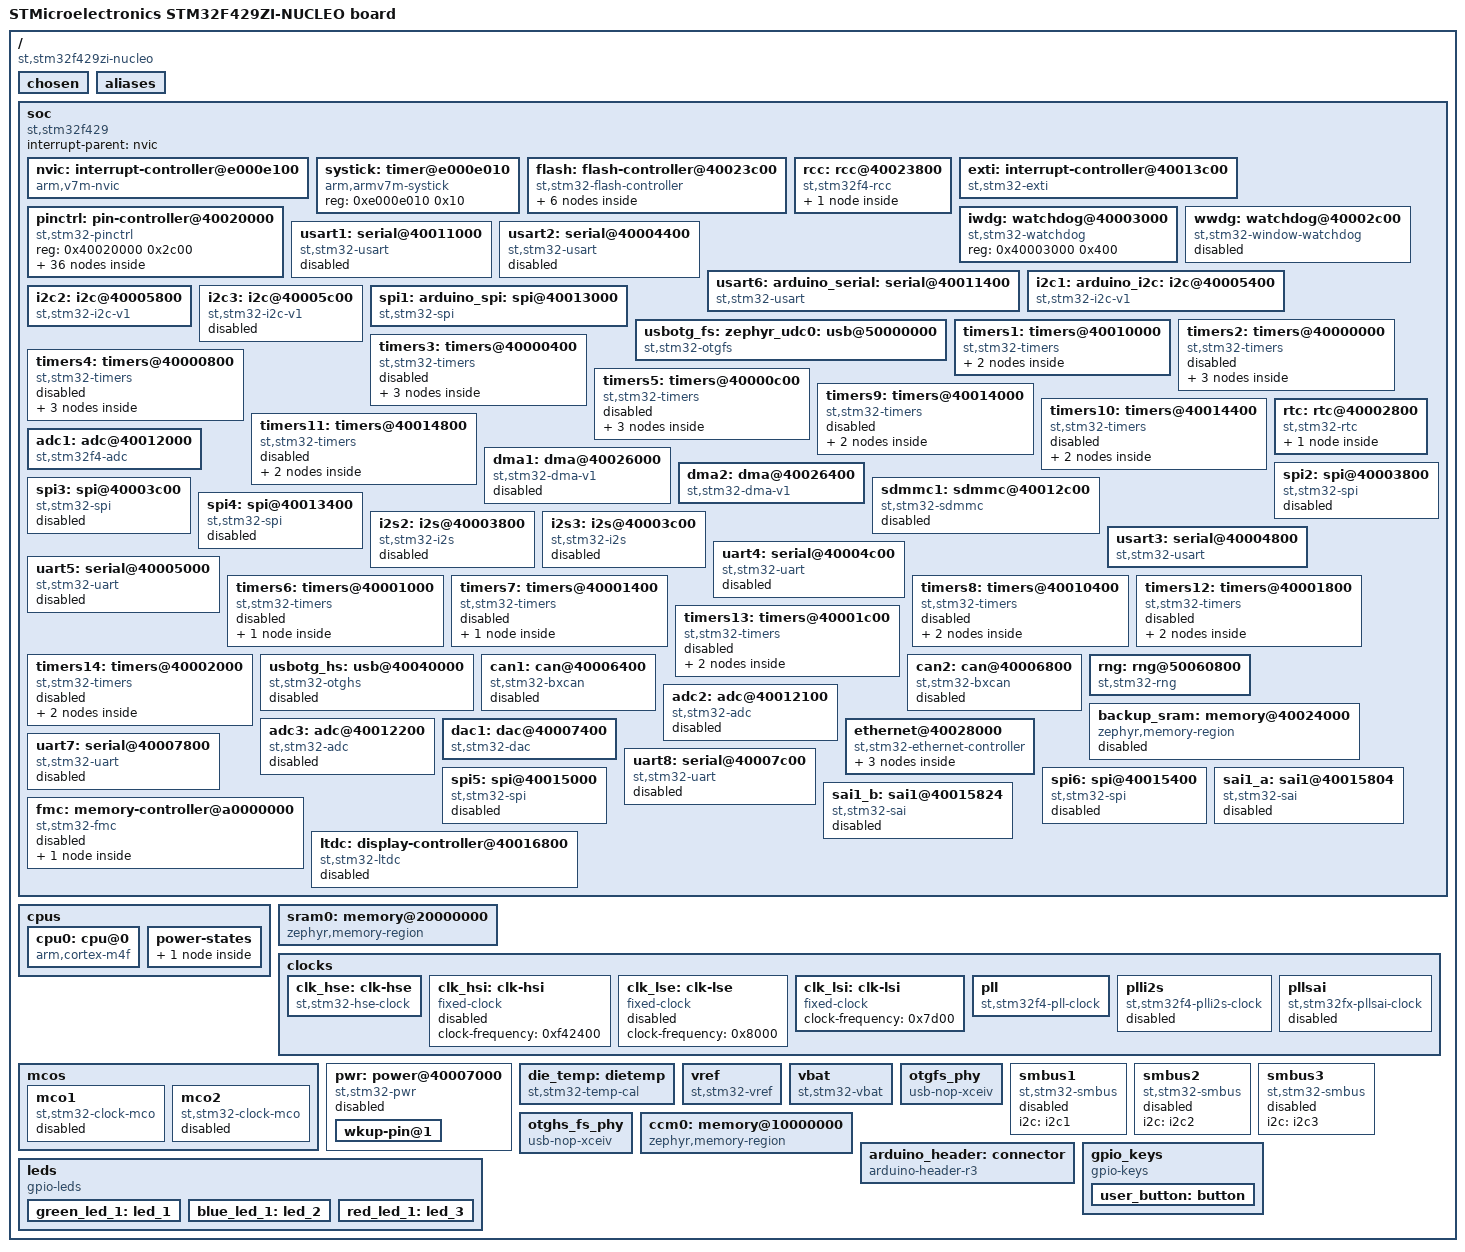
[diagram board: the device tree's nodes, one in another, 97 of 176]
/dts-v1/;

/* node '/' defined in zephyr/dts/common/skeleton.dtsi:9 */
/ {
	#address-cells = < 0x1 >;                              /* in zephyr/dts/common/skeleton.dtsi:10 */
	#size-cells = < 0x1 >;                                 /* in zephyr/dts/common/skeleton.dtsi:11 */
	model = "STMicroelectronics STM32F429ZI-NUCLEO board"; /* in zephyr/boards/st/nucleo_f429zi/nucleo_f429zi.dts:14 */
	compatible = "st,stm32f429zi-nucleo";                  /* in zephyr/boards/st/nucleo_f429zi/nucleo_f429zi.dts:15 */

	/* node '/chosen' defined in zephyr/dts/common/skeleton.dtsi:13 */
	chosen {
		zephyr,flash-controller = &flash;         /* in zephyr/dts/arm/st/f4/stm32f4.dtsi:27 */
		zephyr,cortex-m-idle-timer = &rtc;        /* in zephyr/dts/arm/st/f4/stm32f4.dtsi:28 */
		zephyr,entropy = &rng;                    /* in zephyr/dts/arm/st/f4/stm32f405.dtsi:13 */
		zephyr,console = &usart3;                 /* in zephyr/boards/st/nucleo_f429zi/nucleo_f429zi.dts:18 */
		zephyr,shell-uart = &usart3;              /* in zephyr/boards/st/nucleo_f429zi/nucleo_f429zi.dts:19 */
		zephyr,sram = &sram0;                     /* in zephyr/boards/st/nucleo_f429zi/nucleo_f429zi.dts:20 */
		zephyr,flash = &flash0;                   /* in zephyr/boards/st/nucleo_f429zi/nucleo_f429zi.dts:21 */
		zephyr,ccm = &ccm0;                       /* in zephyr/boards/st/nucleo_f429zi/nucleo_f429zi.dts:22 */
		zephyr,code-partition = &slot0_partition; /* in zephyr/boards/st/nucleo_f429zi/nucleo_f429zi.dts:23 */
	};

	/* node '/aliases' defined in zephyr/dts/common/skeleton.dtsi:15 */
	aliases {
		led0 = &green_led_1;   /* in zephyr/boards/st/nucleo_f429zi/nucleo_f429zi.dts:56 */
		led1 = &blue_led_1;    /* in zephyr/boards/st/nucleo_f429zi/nucleo_f429zi.dts:57 */
		led2 = &red_led_1;     /* in zephyr/boards/st/nucleo_f429zi/nucleo_f429zi.dts:58 */
		sw0 = &user_button;    /* in zephyr/boards/st/nucleo_f429zi/nucleo_f429zi.dts:59 */
		watchdog0 = &iwdg;     /* in zephyr/boards/st/nucleo_f429zi/nucleo_f429zi.dts:60 */
		die-temp0 = &die_temp; /* in zephyr/boards/st/nucleo_f429zi/nucleo_f429zi.dts:61 */
		volt-sensor0 = &vref;  /* in zephyr/boards/st/nucleo_f429zi/nucleo_f429zi.dts:62 */
		volt-sensor1 = &vbat;  /* in zephyr/boards/st/nucleo_f429zi/nucleo_f429zi.dts:63 */
	};

	/* node '/soc' defined in zephyr/dts/arm/armv7-m.dtsi:6 */
	soc {
		#address-cells = < 0x1 >;     /* in zephyr/dts/arm/armv7-m.dtsi:7 */
		#size-cells = < 0x1 >;        /* in zephyr/dts/arm/armv7-m.dtsi:8 */
		interrupt-parent = < &nvic >; /* in zephyr/dts/arm/armv7-m.dtsi:10 */
		ranges;                       /* in zephyr/dts/arm/armv7-m.dtsi:11 */
		compatible = "st,stm32f429",
		             "st,stm32f4",
		             "simple-bus";    /* in zephyr/dts/arm/st/f4/stm32f429.dtsi:12 */

		/* node '/soc/interrupt-controller@e000e100' defined in zephyr/dts/arm/armv7-m.dtsi:13 */
		nvic: interrupt-controller@e000e100 {
			#address-cells = < 0x1 >;            /* in zephyr/dts/arm/armv7-m.dtsi:14 */
			compatible = "arm,v7m-nvic";         /* in zephyr/dts/arm/armv7-m.dtsi:15 */
			reg = < 0xe000e100 0xc00 >;          /* in zephyr/dts/arm/armv7-m.dtsi:16 */
			interrupt-controller;                /* in zephyr/dts/arm/armv7-m.dtsi:17 */
			#interrupt-cells = < 0x2 >;          /* in zephyr/dts/arm/armv7-m.dtsi:18 */
			arm,num-irq-priority-bits = < 0x4 >; /* in zephyr/dts/arm/st/f4/stm32f4.dtsi:676 */
			phandle = < 0x1 >;                   /* in zephyr/dts/arm/armv7-m.dtsi:10 */
		};

		/* node '/soc/timer@e000e010' defined in zephyr/dts/arm/armv7-m.dtsi:21 */
		systick: timer@e000e010 {
			compatible = "arm,armv7m-systick"; /* in zephyr/dts/arm/armv7-m.dtsi:22 */
			reg = < 0xe000e010 0x10 >;         /* in zephyr/dts/arm/armv7-m.dtsi:23 */
		};

		/* node '/soc/flash-controller@40023c00' defined in zephyr/dts/arm/st/f4/stm32f4.dtsi:111 */
		flash: flash-controller@40023c00 {
			compatible = "st,stm32-flash-controller",
			             "st,stm32f4-flash-controller"; /* in zephyr/dts/arm/st/f4/stm32f4.dtsi:112 */
			reg = < 0x40023c00 0x400 >;                 /* in zephyr/dts/arm/st/f4/stm32f4.dtsi:113 */
			interrupts = < 0x4 0x0 >;                   /* in zephyr/dts/arm/st/f4/stm32f4.dtsi:114 */
			#address-cells = < 0x1 >;                   /* in zephyr/dts/arm/st/f4/stm32f4.dtsi:116 */
			#size-cells = < 0x1 >;                      /* in zephyr/dts/arm/st/f4/stm32f4.dtsi:117 */

			/* node '/soc/flash-controller@40023c00/flash@8000000' defined in zephyr/dts/arm/st/f4/stm32f4.dtsi:119 */
			flash0: flash@8000000 {
				compatible = "st,stm32f4-nv-flash",
				             "st,stm32-nv-flash",
				             "soc-nv-flash";        /* in zephyr/dts/arm/st/f4/stm32f4.dtsi:120 */
				write-block-size = < 0x1 >;         /* in zephyr/dts/arm/st/f4/stm32f4.dtsi:123 */
				max-erase-time = < 0xfa0 >;         /* in zephyr/dts/arm/st/f4/stm32f4.dtsi:125 */
				reg = < 0x8000000 0x200000 >;       /* in zephyr/dts/arm/st/f4/stm32f429Xi.dtsi:23 */

				/* node '/soc/flash-controller@40023c00/flash@8000000/partitions' defined in zephyr/boards/st/nucleo_f429zi/nucleo_f429zi.dts:208 */
				partitions {
					compatible = "fixed-partitions"; /* in zephyr/boards/st/nucleo_f429zi/nucleo_f429zi.dts:209 */
					#address-cells = < 0x1 >;        /* in zephyr/boards/st/nucleo_f429zi/nucleo_f429zi.dts:210 */
					#size-cells = < 0x1 >;           /* in zephyr/boards/st/nucleo_f429zi/nucleo_f429zi.dts:211 */

					/* node '/soc/flash-controller@40023c00/flash@8000000/partitions/partition@0' defined in zephyr/boards/st/nucleo_f429zi/nucleo_f429zi.dts:214 */
					boot_partition: partition@0 {
						label = "mcuboot";    /* in zephyr/boards/st/nucleo_f429zi/nucleo_f429zi.dts:215 */
						reg = < 0x0 0x8000 >; /* in zephyr/boards/st/nucleo_f429zi/nucleo_f429zi.dts:216 */
						read-only;            /* in zephyr/boards/st/nucleo_f429zi/nucleo_f429zi.dts:217 */
					};

					/* node '/soc/flash-controller@40023c00/flash@8000000/partitions/partition@20000' defined in zephyr/boards/st/nucleo_f429zi/nucleo_f429zi.dts:233 */
					slot0_partition: partition@20000 {
						label = "image-0";         /* in zephyr/boards/st/nucleo_f429zi/nucleo_f429zi.dts:234 */
						reg = < 0x20000 0x40000 >; /* in zephyr/boards/st/nucleo_f429zi/nucleo_f429zi.dts:235 */
					};

					/* node '/soc/flash-controller@40023c00/flash@8000000/partitions/partition@60000' defined in zephyr/boards/st/nucleo_f429zi/nucleo_f429zi.dts:239 */
					slot1_partition: partition@60000 {
						label = "image-1";         /* in zephyr/boards/st/nucleo_f429zi/nucleo_f429zi.dts:240 */
						reg = < 0x60000 0x40000 >; /* in zephyr/boards/st/nucleo_f429zi/nucleo_f429zi.dts:241 */
					};

					/* node '/soc/flash-controller@40023c00/flash@8000000/partitions/partition@a0000' defined in zephyr/boards/st/nucleo_f429zi/nucleo_f429zi.dts:245 */
					scratch_partition: partition@a0000 {
						label = "image-scratch";   /* in zephyr/boards/st/nucleo_f429zi/nucleo_f429zi.dts:246 */
						reg = < 0xa0000 0x20000 >; /* in zephyr/boards/st/nucleo_f429zi/nucleo_f429zi.dts:247 */
					};
				};
			};
		};

		/* node '/soc/rcc@40023800' defined in zephyr/dts/arm/st/f4/stm32f4.dtsi:129 */
		rcc: rcc@40023800 {
			#clock-cells = < 0x2 >;          /* in zephyr/dts/arm/st/f4/stm32f4.dtsi:131 */
			reg = < 0x40023800 0x400 >;      /* in zephyr/dts/arm/st/f4/stm32f4.dtsi:132 */
			compatible = "st,stm32f4-rcc";   /* in zephyr/dts/arm/st/f4/stm32f427.dtsi:25 */
			clocks = < &pll >;               /* in zephyr/boards/st/nucleo_f429zi/nucleo_f429zi.dts:87 */
			clock-frequency = < 0xa037a00 >; /* in zephyr/boards/st/nucleo_f429zi/nucleo_f429zi.dts:88 */
			ahb-prescaler = < 0x1 >;         /* in zephyr/boards/st/nucleo_f429zi/nucleo_f429zi.dts:89 */
			apb1-prescaler = < 0x4 >;        /* in zephyr/boards/st/nucleo_f429zi/nucleo_f429zi.dts:90 */
			apb2-prescaler = < 0x2 >;        /* in zephyr/boards/st/nucleo_f429zi/nucleo_f429zi.dts:91 */
			phandle = < 0x3 >;               /* in zephyr/dts/arm/st/f4/stm32f4.dtsi:146 */

			/* node '/soc/rcc@40023800/reset-controller' defined in zephyr/dts/arm/st/f4/stm32f4.dtsi:134 */
			rctl: reset-controller {
				compatible = "st,stm32-rcc-rctl"; /* in zephyr/dts/arm/st/f4/stm32f4.dtsi:135 */
				#reset-cells = < 0x1 >;           /* in zephyr/dts/arm/st/f4/stm32f4.dtsi:136 */
				phandle = < 0x4 >;                /* in zephyr/dts/arm/st/f4/stm32f4.dtsi:245 */
			};
		};

		/* node '/soc/interrupt-controller@40013c00' defined in zephyr/dts/arm/st/f4/stm32f4.dtsi:140 */
		exti: interrupt-controller@40013c00 {
			compatible = "st,stm32-exti";  /* in zephyr/dts/arm/st/f4/stm32f4.dtsi:141 */
			interrupt-controller;          /* in zephyr/dts/arm/st/f4/stm32f4.dtsi:142 */
			#interrupt-cells = < 0x1 >;    /* in zephyr/dts/arm/st/f4/stm32f4.dtsi:143 */
			#address-cells = < 0x0 >;      /* in zephyr/dts/arm/st/f4/stm32f4.dtsi:144 */
			reg = < 0x40013c00 0x400 >;    /* in zephyr/dts/arm/st/f4/stm32f4.dtsi:145 */
			clocks = < &rcc 0x44 0x4000 >; /* in zephyr/dts/arm/st/f4/stm32f4.dtsi:146 */
			num-lines = < 0x20 >;          /* in zephyr/dts/arm/st/f4/stm32f4.dtsi:147 */
			interrupts = < 0x6 0x0 >,
			             < 0x7 0x0 >,
			             < 0x8 0x0 >,
			             < 0x9 0x0 >,
			             < 0xa 0x0 >,
			             < 0x17 0x0 >,
			             < 0x28 0x0 >;     /* in zephyr/dts/arm/st/f4/stm32f4.dtsi:148 */
			interrupt-names = "line0",
			                  "line1",
			                  "line2",
			                  "line3",
			                  "line4",
			                  "line5-9",
			                  "line10-15"; /* in zephyr/dts/arm/st/f4/stm32f4.dtsi:150 */
			line-ranges = < 0x0 0x1 >,
			              < 0x1 0x1 >,
			              < 0x2 0x1 >,
			              < 0x3 0x1 >,
			              < 0x4 0x1 >,
			              < 0x5 0x5 >,
			              < 0xa 0x6 >;     /* in zephyr/dts/arm/st/f4/stm32f4.dtsi:152 */
		};

		/* node '/soc/pin-controller@40020000' defined in zephyr/dts/arm/st/f4/stm32f4.dtsi:156 */
		pinctrl: pin-controller@40020000 {
			compatible = "st,stm32-pinctrl"; /* in zephyr/dts/arm/st/f4/stm32f4.dtsi:157 */
			#address-cells = < 0x1 >;        /* in zephyr/dts/arm/st/f4/stm32f4.dtsi:158 */
			#size-cells = < 0x1 >;           /* in zephyr/dts/arm/st/f4/stm32f4.dtsi:159 */
			reg = < 0x40020000 0x2c00 >;     /* in zephyr/dts/arm/st/f4/stm32f427.dtsi:29 */

			/* node '/soc/pin-controller@40020000/gpio@40020000' defined in zephyr/dts/arm/st/f4/stm32f4.dtsi:162 */
			gpioa: gpio@40020000 {
				compatible = "st,stm32-gpio"; /* in zephyr/dts/arm/st/f4/stm32f4.dtsi:163 */
				gpio-controller;              /* in zephyr/dts/arm/st/f4/stm32f4.dtsi:164 */
				#gpio-cells = < 0x2 >;        /* in zephyr/dts/arm/st/f4/stm32f4.dtsi:165 */
				reg = < 0x40020000 0x400 >;   /* in zephyr/dts/arm/st/f4/stm32f4.dtsi:166 */
				clocks = < &rcc 0x30 0x1 >;   /* in zephyr/dts/arm/st/f4/stm32f4.dtsi:167 */
				phandle = < 0x26 >;           /* in zephyr/dts/arm/st/f4/stm32f4.dtsi:615 */
			};

			/* node '/soc/pin-controller@40020000/gpio@40020400' defined in zephyr/dts/arm/st/f4/stm32f4.dtsi:170 */
			gpiob: gpio@40020400 {
				compatible = "st,stm32-gpio"; /* in zephyr/dts/arm/st/f4/stm32f4.dtsi:171 */
				gpio-controller;              /* in zephyr/dts/arm/st/f4/stm32f4.dtsi:172 */
				#gpio-cells = < 0x2 >;        /* in zephyr/dts/arm/st/f4/stm32f4.dtsi:173 */
				reg = < 0x40020400 0x400 >;   /* in zephyr/dts/arm/st/f4/stm32f4.dtsi:174 */
				clocks = < &rcc 0x30 0x2 >;   /* in zephyr/dts/arm/st/f4/stm32f4.dtsi:175 */
				phandle = < 0x2f >;           /* in zephyr/boards/st/nucleo_f429zi/arduino_r3_connector.dtsi:15 */
			};

			/* node '/soc/pin-controller@40020000/gpio@40020800' defined in zephyr/dts/arm/st/f4/stm32f4.dtsi:178 */
			gpioc: gpio@40020800 {
				compatible = "st,stm32-gpio"; /* in zephyr/dts/arm/st/f4/stm32f4.dtsi:179 */
				gpio-controller;              /* in zephyr/dts/arm/st/f4/stm32f4.dtsi:180 */
				#gpio-cells = < 0x2 >;        /* in zephyr/dts/arm/st/f4/stm32f4.dtsi:181 */
				reg = < 0x40020800 0x400 >;   /* in zephyr/dts/arm/st/f4/stm32f4.dtsi:182 */
				clocks = < &rcc 0x30 0x4 >;   /* in zephyr/dts/arm/st/f4/stm32f4.dtsi:183 */
				phandle = < 0x2b >;           /* in zephyr/boards/st/nucleo_f429zi/arduino_r3_connector.dtsi:15 */
			};

			/* node '/soc/pin-controller@40020000/gpio@40020c00' defined in zephyr/dts/arm/st/f4/stm32f4.dtsi:186 */
			gpiod: gpio@40020c00 {
				compatible = "st,stm32-gpio"; /* in zephyr/dts/arm/st/f4/stm32f4.dtsi:187 */
				gpio-controller;              /* in zephyr/dts/arm/st/f4/stm32f4.dtsi:188 */
				#gpio-cells = < 0x2 >;        /* in zephyr/dts/arm/st/f4/stm32f4.dtsi:189 */
				reg = < 0x40020c00 0x400 >;   /* in zephyr/dts/arm/st/f4/stm32f4.dtsi:190 */
				clocks = < &rcc 0x30 0x8 >;   /* in zephyr/dts/arm/st/f4/stm32f4.dtsi:191 */
				phandle = < 0xe >;            /* in zephyr/boards/st/nucleo_f429zi/nucleo_f429zi.dts:129 */
			};

			/* node '/soc/pin-controller@40020000/gpio@40021000' defined in zephyr/dts/arm/st/f4/stm32f4.dtsi:194 */
			gpioe: gpio@40021000 {
				compatible = "st,stm32-gpio"; /* in zephyr/dts/arm/st/f4/stm32f4.dtsi:195 */
				gpio-controller;              /* in zephyr/dts/arm/st/f4/stm32f4.dtsi:196 */
				#gpio-cells = < 0x2 >;        /* in zephyr/dts/arm/st/f4/stm32f4.dtsi:197 */
				reg = < 0x40021000 0x400 >;   /* in zephyr/dts/arm/st/f4/stm32f4.dtsi:198 */
				clocks = < &rcc 0x30 0x10 >;  /* in zephyr/dts/arm/st/f4/stm32f4.dtsi:199 */
				phandle = < 0x2e >;           /* in zephyr/boards/st/nucleo_f429zi/arduino_r3_connector.dtsi:15 */
			};

			/* node '/soc/pin-controller@40020000/gpio@40021400' defined in zephyr/dts/arm/st/f4/stm32f4.dtsi:202 */
			gpiof: gpio@40021400 {
				compatible = "st,stm32-gpio"; /* in zephyr/dts/arm/st/f4/stm32f405.dtsi:27 */
				gpio-controller;              /* in zephyr/dts/arm/st/f4/stm32f405.dtsi:28 */
				#gpio-cells = < 0x2 >;        /* in zephyr/dts/arm/st/f4/stm32f405.dtsi:29 */
				reg = < 0x40021400 0x400 >;   /* in zephyr/dts/arm/st/f4/stm32f405.dtsi:30 */
				clocks = < &rcc 0x30 0x20 >;  /* in zephyr/dts/arm/st/f4/stm32f405.dtsi:31 */
				phandle = < 0x2c >;           /* in zephyr/boards/st/nucleo_f429zi/arduino_r3_connector.dtsi:15 */
			};

			/* node '/soc/pin-controller@40020000/gpio@40021800' defined in zephyr/dts/arm/st/f4/stm32f4.dtsi:210 */
			gpiog: gpio@40021800 {
				compatible = "st,stm32-gpio"; /* in zephyr/dts/arm/st/f4/stm32f405.dtsi:35 */
				gpio-controller;              /* in zephyr/dts/arm/st/f4/stm32f405.dtsi:36 */
				#gpio-cells = < 0x2 >;        /* in zephyr/dts/arm/st/f4/stm32f405.dtsi:37 */
				reg = < 0x40021800 0x400 >;   /* in zephyr/dts/arm/st/f4/stm32f405.dtsi:38 */
				clocks = < &rcc 0x30 0x40 >;  /* in zephyr/dts/arm/st/f4/stm32f405.dtsi:39 */
				phandle = < 0x2d >;           /* in zephyr/boards/st/nucleo_f429zi/arduino_r3_connector.dtsi:15 */
			};

			/* node '/soc/pin-controller@40020000/gpio@40021c00' defined in zephyr/dts/arm/st/f4/stm32f4.dtsi:218 */
			gpioh: gpio@40021c00 {
				compatible = "st,stm32-gpio"; /* in zephyr/dts/arm/st/f4/stm32f4.dtsi:219 */
				gpio-controller;              /* in zephyr/dts/arm/st/f4/stm32f4.dtsi:220 */
				#gpio-cells = < 0x2 >;        /* in zephyr/dts/arm/st/f4/stm32f4.dtsi:221 */
				reg = < 0x40021c00 0x400 >;   /* in zephyr/dts/arm/st/f4/stm32f4.dtsi:222 */
				clocks = < &rcc 0x30 0x80 >;  /* in zephyr/dts/arm/st/f4/stm32f4.dtsi:223 */
			};

			/* node '/soc/pin-controller@40020000/gpio@40022000' defined in zephyr/dts/arm/st/f4/stm32f405.dtsi:42 */
			gpioi: gpio@40022000 {
				compatible = "st,stm32-gpio"; /* in zephyr/dts/arm/st/f4/stm32f405.dtsi:43 */
				gpio-controller;              /* in zephyr/dts/arm/st/f4/stm32f405.dtsi:44 */
				#gpio-cells = < 0x2 >;        /* in zephyr/dts/arm/st/f4/stm32f405.dtsi:45 */
				reg = < 0x40022000 0x400 >;   /* in zephyr/dts/arm/st/f4/stm32f405.dtsi:46 */
				clocks = < &rcc 0x30 0x100 >; /* in zephyr/dts/arm/st/f4/stm32f405.dtsi:47 */
			};

			/* node '/soc/pin-controller@40020000/gpio@40022400' defined in zephyr/dts/arm/st/f4/stm32f427.dtsi:31 */
			gpioj: gpio@40022400 {
				compatible = "st,stm32-gpio"; /* in zephyr/dts/arm/st/f4/stm32f427.dtsi:32 */
				gpio-controller;              /* in zephyr/dts/arm/st/f4/stm32f427.dtsi:33 */
				#gpio-cells = < 0x2 >;        /* in zephyr/dts/arm/st/f4/stm32f427.dtsi:34 */
				reg = < 0x40022400 0x400 >;   /* in zephyr/dts/arm/st/f4/stm32f427.dtsi:35 */
				clocks = < &rcc 0x30 0x200 >; /* in zephyr/dts/arm/st/f4/stm32f427.dtsi:36 */
			};

			/* node '/soc/pin-controller@40020000/gpio@40022800' defined in zephyr/dts/arm/st/f4/stm32f427.dtsi:39 */
			gpiok: gpio@40022800 {
				compatible = "st,stm32-gpio"; /* in zephyr/dts/arm/st/f4/stm32f427.dtsi:40 */
				gpio-controller;              /* in zephyr/dts/arm/st/f4/stm32f427.dtsi:41 */
				#gpio-cells = < 0x2 >;        /* in zephyr/dts/arm/st/f4/stm32f427.dtsi:42 */
				reg = < 0x40022800 0x400 >;   /* in zephyr/dts/arm/st/f4/stm32f427.dtsi:43 */
				clocks = < &rcc 0x30 0x400 >; /* in zephyr/dts/arm/st/f4/stm32f427.dtsi:44 */
			};

			/* node '/soc/pin-controller@40020000/adc1_in0_pa0' defined in modules/hal/stm32/dts/st/f4/stm32f429zitx-pinctrl.dtsi:15 */
			adc1_in0_pa0: adc1_in0_pa0 {
				pinmux = < 0x10 >;  /* in modules/hal/stm32/dts/st/f4/stm32f429zitx-pinctrl.dtsi:16 */
				phandle = < 0x13 >; /* in zephyr/boards/st/nucleo_f429zi/nucleo_f429zi.dts:95 */
			};

			/* node '/soc/pin-controller@40020000/dac_out1_pa4' defined in modules/hal/stm32/dts/st/f4/stm32f429zitx-pinctrl.dtsi:716 */
			dac_out1_pa4: dac_out1_pa4 {
				pinmux = < 0x90 >;  /* in modules/hal/stm32/dts/st/f4/stm32f429zitx-pinctrl.dtsi:717 */
				phandle = < 0x18 >; /* in zephyr/boards/st/nucleo_f429zi/nucleo_f429zi.dts:108 */
			};

			/* node '/soc/pin-controller@40020000/eth_ref_clk_pa1' defined in modules/hal/stm32/dts/st/f4/stm32f429zitx-pinctrl.dtsi:893 */
			eth_ref_clk_pa1: eth_ref_clk_pa1 {
				pinmux = < 0x2b >;             /* in modules/hal/stm32/dts/st/f4/stm32f429zitx-pinctrl.dtsi:894 */
				slew-rate = "very-high-speed"; /* in modules/hal/stm32/dts/st/f4/stm32f429zitx-pinctrl.dtsi:895 */
				phandle = < 0x1b >;            /* in zephyr/boards/st/nucleo_f429zi/nucleo_f429zi.dts:184 */
			};

			/* node '/soc/pin-controller@40020000/eth_mdio_pa2' defined in modules/hal/stm32/dts/st/f4/stm32f429zitx-pinctrl.dtsi:903 */
			eth_mdio_pa2: eth_mdio_pa2 {
				pinmux = < 0x4b >;             /* in modules/hal/stm32/dts/st/f4/stm32f429zitx-pinctrl.dtsi:904 */
				slew-rate = "very-high-speed"; /* in modules/hal/stm32/dts/st/f4/stm32f429zitx-pinctrl.dtsi:905 */
				phandle = < 0x21 >;            /* in zephyr/boards/st/nucleo_f429zi/nucleo_f429zi.dts:198 */
			};

			/* node '/soc/pin-controller@40020000/eth_crs_dv_pa7' defined in modules/hal/stm32/dts/st/f4/stm32f429zitx-pinctrl.dtsi:913 */
			eth_crs_dv_pa7: eth_crs_dv_pa7 {
				pinmux = < 0xeb >;             /* in modules/hal/stm32/dts/st/f4/stm32f429zitx-pinctrl.dtsi:914 */
				slew-rate = "very-high-speed"; /* in modules/hal/stm32/dts/st/f4/stm32f429zitx-pinctrl.dtsi:915 */
				phandle = < 0x1c >;            /* in zephyr/boards/st/nucleo_f429zi/nucleo_f429zi.dts:184 */
			};

			/* node '/soc/pin-controller@40020000/eth_txd1_pb13' defined in modules/hal/stm32/dts/st/f4/stm32f429zitx-pinctrl.dtsi:958 */
			eth_txd1_pb13: eth_txd1_pb13 {
				pinmux = < 0x3ab >;            /* in modules/hal/stm32/dts/st/f4/stm32f429zitx-pinctrl.dtsi:959 */
				slew-rate = "very-high-speed"; /* in modules/hal/stm32/dts/st/f4/stm32f429zitx-pinctrl.dtsi:960 */
				phandle = < 0x1f >;            /* in zephyr/boards/st/nucleo_f429zi/nucleo_f429zi.dts:184 */
			};

			/* node '/soc/pin-controller@40020000/eth_mdc_pc1' defined in modules/hal/stm32/dts/st/f4/stm32f429zitx-pinctrl.dtsi:963 */
			eth_mdc_pc1: eth_mdc_pc1 {
				pinmux = < 0x42b >;            /* in modules/hal/stm32/dts/st/f4/stm32f429zitx-pinctrl.dtsi:964 */
				slew-rate = "very-high-speed"; /* in modules/hal/stm32/dts/st/f4/stm32f429zitx-pinctrl.dtsi:965 */
				phandle = < 0x22 >;            /* in zephyr/boards/st/nucleo_f429zi/nucleo_f429zi.dts:198 */
			};

			/* node '/soc/pin-controller@40020000/eth_rxd0_pc4' defined in modules/hal/stm32/dts/st/f4/stm32f429zitx-pinctrl.dtsi:978 */
			eth_rxd0_pc4: eth_rxd0_pc4 {
				pinmux = < 0x48b >;            /* in modules/hal/stm32/dts/st/f4/stm32f429zitx-pinctrl.dtsi:979 */
				slew-rate = "very-high-speed"; /* in modules/hal/stm32/dts/st/f4/stm32f429zitx-pinctrl.dtsi:980 */
				phandle = < 0x19 >;            /* in zephyr/boards/st/nucleo_f429zi/nucleo_f429zi.dts:184 */
			};

			/* node '/soc/pin-controller@40020000/eth_rxd1_pc5' defined in modules/hal/stm32/dts/st/f4/stm32f429zitx-pinctrl.dtsi:983 */
			eth_rxd1_pc5: eth_rxd1_pc5 {
				pinmux = < 0x4ab >;            /* in modules/hal/stm32/dts/st/f4/stm32f429zitx-pinctrl.dtsi:984 */
				slew-rate = "very-high-speed"; /* in modules/hal/stm32/dts/st/f4/stm32f429zitx-pinctrl.dtsi:985 */
				phandle = < 0x1a >;            /* in zephyr/boards/st/nucleo_f429zi/nucleo_f429zi.dts:184 */
			};

			/* node '/soc/pin-controller@40020000/eth_tx_en_pg11' defined in modules/hal/stm32/dts/st/f4/stm32f429zitx-pinctrl.dtsi:998 */
			eth_tx_en_pg11: eth_tx_en_pg11 {
				pinmux = < 0xd6b >;            /* in modules/hal/stm32/dts/st/f4/stm32f429zitx-pinctrl.dtsi:999 */
				slew-rate = "very-high-speed"; /* in modules/hal/stm32/dts/st/f4/stm32f429zitx-pinctrl.dtsi:1000 */
				phandle = < 0x1d >;            /* in zephyr/boards/st/nucleo_f429zi/nucleo_f429zi.dts:184 */
			};

			/* node '/soc/pin-controller@40020000/eth_txd0_pg13' defined in modules/hal/stm32/dts/st/f4/stm32f429zitx-pinctrl.dtsi:1003 */
			eth_txd0_pg13: eth_txd0_pg13 {
				pinmux = < 0xdab >;            /* in modules/hal/stm32/dts/st/f4/stm32f429zitx-pinctrl.dtsi:1004 */
				slew-rate = "very-high-speed"; /* in modules/hal/stm32/dts/st/f4/stm32f429zitx-pinctrl.dtsi:1005 */
				phandle = < 0x1e >;            /* in zephyr/boards/st/nucleo_f429zi/nucleo_f429zi.dts:184 */
			};

			/* node '/soc/pin-controller@40020000/i2c1_scl_pb8' defined in modules/hal/stm32/dts/st/f4/stm32f429zitx-pinctrl.dtsi:1401 */
			i2c1_scl_pb8: i2c1_scl_pb8 {
				pinmux = < 0x304 >; /* in modules/hal/stm32/dts/st/f4/stm32f429zitx-pinctrl.dtsi:1402 */
				bias-pull-up;       /* in modules/hal/stm32/dts/st/f4/stm32f429zitx-pinctrl.dtsi:1403 */
				drive-open-drain;   /* in modules/hal/stm32/dts/st/f4/stm32f429zitx-pinctrl.dtsi:1404 */
				phandle = < 0x7 >;  /* in zephyr/boards/st/nucleo_f429zi/nucleo_f429zi.dts:113 */
			};

			/* node '/soc/pin-controller@40020000/i2c2_scl_pb10' defined in modules/hal/stm32/dts/st/f4/stm32f429zitx-pinctrl.dtsi:1407 */
			i2c2_scl_pb10: i2c2_scl_pb10 {
				pinmux = < 0x344 >; /* in modules/hal/stm32/dts/st/f4/stm32f429zitx-pinctrl.dtsi:1408 */
				bias-pull-up;       /* in modules/hal/stm32/dts/st/f4/stm32f429zitx-pinctrl.dtsi:1409 */
				drive-open-drain;   /* in modules/hal/stm32/dts/st/f4/stm32f429zitx-pinctrl.dtsi:1410 */
				phandle = < 0x9 >;  /* in zephyr/boards/st/nucleo_f429zi/nucleo_f429zi.dts:120 */
			};

			/* node '/soc/pin-controller@40020000/i2c1_sda_pb9' defined in modules/hal/stm32/dts/st/f4/stm32f429zitx-pinctrl.dtsi:1433 */
			i2c1_sda_pb9: i2c1_sda_pb9 {
				pinmux = < 0x324 >; /* in modules/hal/stm32/dts/st/f4/stm32f429zitx-pinctrl.dtsi:1434 */
				bias-pull-up;       /* in modules/hal/stm32/dts/st/f4/stm32f429zitx-pinctrl.dtsi:1435 */
				drive-open-drain;   /* in modules/hal/stm32/dts/st/f4/stm32f429zitx-pinctrl.dtsi:1436 */
				phandle = < 0x8 >;  /* in zephyr/boards/st/nucleo_f429zi/nucleo_f429zi.dts:113 */
			};

			/* node '/soc/pin-controller@40020000/i2c2_sda_pb11' defined in modules/hal/stm32/dts/st/f4/stm32f429zitx-pinctrl.dtsi:1439 */
			i2c2_sda_pb11: i2c2_sda_pb11 {
				pinmux = < 0x364 >; /* in modules/hal/stm32/dts/st/f4/stm32f429zitx-pinctrl.dtsi:1440 */
				bias-pull-up;       /* in modules/hal/stm32/dts/st/f4/stm32f429zitx-pinctrl.dtsi:1441 */
				drive-open-drain;   /* in modules/hal/stm32/dts/st/f4/stm32f429zitx-pinctrl.dtsi:1442 */
				phandle = < 0xa >;  /* in zephyr/boards/st/nucleo_f429zi/nucleo_f429zi.dts:120 */
			};

			/* node '/soc/pin-controller@40020000/spi1_miso_pa6' defined in modules/hal/stm32/dts/st/f4/stm32f429zitx-pinctrl.dtsi:1836 */
			spi1_miso_pa6: spi1_miso_pa6 {
				pinmux = < 0xc5 >; /* in modules/hal/stm32/dts/st/f4/stm32f429zitx-pinctrl.dtsi:1837 */
				bias-pull-down;    /* in modules/hal/stm32/dts/st/f4/stm32f429zitx-pinctrl.dtsi:1838 */
				phandle = < 0xc >; /* in zephyr/boards/st/nucleo_f429zi/nucleo_f429zi.dts:127 */
			};

			/* node '/soc/pin-controller@40020000/spi1_mosi_pa7' defined in modules/hal/stm32/dts/st/f4/stm32f429zitx-pinctrl.dtsi:1888 */
			spi1_mosi_pa7: spi1_mosi_pa7 {
				pinmux = < 0xe5 >; /* in modules/hal/stm32/dts/st/f4/stm32f429zitx-pinctrl.dtsi:1889 */
				bias-pull-down;    /* in modules/hal/stm32/dts/st/f4/stm32f429zitx-pinctrl.dtsi:1890 */
				phandle = < 0xd >; /* in zephyr/boards/st/nucleo_f429zi/nucleo_f429zi.dts:127 */
			};

			/* node '/soc/pin-controller@40020000/spi1_sck_pa5' defined in modules/hal/stm32/dts/st/f4/stm32f429zitx-pinctrl.dtsi:2002 */
			spi1_sck_pa5: spi1_sck_pa5 {
				pinmux = < 0xa5 >;             /* in modules/hal/stm32/dts/st/f4/stm32f429zitx-pinctrl.dtsi:2003 */
				bias-pull-down;                /* in modules/hal/stm32/dts/st/f4/stm32f429zitx-pinctrl.dtsi:2004 */
				slew-rate = "very-high-speed"; /* in modules/hal/stm32/dts/st/f4/stm32f429zitx-pinctrl.dtsi:2005 */
				phandle = < 0xb >;             /* in zephyr/boards/st/nucleo_f429zi/nucleo_f429zi.dts:127 */
			};

			/* node '/soc/pin-controller@40020000/tim1_ch3_pe13' defined in modules/hal/stm32/dts/st/f4/stm32f429zitx-pinctrl.dtsi:2160 */
			tim1_ch3_pe13: tim1_ch3_pe13 {
				pinmux = < 0x9a1 >; /* in modules/hal/stm32/dts/st/f4/stm32f429zitx-pinctrl.dtsi:2161 */
				phandle = < 0x12 >; /* in zephyr/boards/st/nucleo_f429zi/nucleo_f429zi.dts:159 */
			};

			/* node '/soc/pin-controller@40020000/usart3_rx_pd9' defined in modules/hal/stm32/dts/st/f4/stm32f429zitx-pinctrl.dtsi:2476 */
			usart3_rx_pd9: usart3_rx_pd9 {
				pinmux = < 0x727 >; /* in modules/hal/stm32/dts/st/f4/stm32f429zitx-pinctrl.dtsi:2477 */
				phandle = < 0x16 >; /* in zephyr/boards/st/nucleo_f429zi/nucleo_f429zi.dts:134 */
			};

			/* node '/soc/pin-controller@40020000/usart6_rx_pg9' defined in modules/hal/stm32/dts/st/f4/stm32f429zitx-pinctrl.dtsi:2496 */
			usart6_rx_pg9: usart6_rx_pg9 {
				pinmux = < 0xd28 >; /* in modules/hal/stm32/dts/st/f4/stm32f429zitx-pinctrl.dtsi:2497 */
				phandle = < 0x6 >;  /* in zephyr/boards/st/nucleo_f429zi/nucleo_f429zi.dts:141 */
			};

			/* node '/soc/pin-controller@40020000/usart3_tx_pd8' defined in modules/hal/stm32/dts/st/f4/stm32f429zitx-pinctrl.dtsi:2544 */
			usart3_tx_pd8: usart3_tx_pd8 {
				pinmux = < 0x707 >; /* in modules/hal/stm32/dts/st/f4/stm32f429zitx-pinctrl.dtsi:2545 */
				bias-pull-up;       /* in modules/hal/stm32/dts/st/f4/stm32f429zitx-pinctrl.dtsi:2546 */
				phandle = < 0x15 >; /* in zephyr/boards/st/nucleo_f429zi/nucleo_f429zi.dts:134 */
			};

			/* node '/soc/pin-controller@40020000/usart6_tx_pg14' defined in modules/hal/stm32/dts/st/f4/stm32f429zitx-pinctrl.dtsi:2569 */
			usart6_tx_pg14: usart6_tx_pg14 {
				pinmux = < 0xdc8 >; /* in modules/hal/stm32/dts/st/f4/stm32f429zitx-pinctrl.dtsi:2570 */
				bias-pull-up;       /* in modules/hal/stm32/dts/st/f4/stm32f429zitx-pinctrl.dtsi:2571 */
				phandle = < 0x5 >;  /* in zephyr/boards/st/nucleo_f429zi/nucleo_f429zi.dts:141 */
			};

			/* node '/soc/pin-controller@40020000/usb_otg_fs_dm_pa11' defined in modules/hal/stm32/dts/st/f4/stm32f429zitx-pinctrl.dtsi:2603 */
			usb_otg_fs_dm_pa11: usb_otg_fs_dm_pa11 {
				pinmux = < 0x16a >; /* in modules/hal/stm32/dts/st/f4/stm32f429zitx-pinctrl.dtsi:2604 */
				phandle = < 0x10 >; /* in zephyr/boards/st/nucleo_f429zi/nucleo_f429zi.dts:148 */
			};

			/* node '/soc/pin-controller@40020000/usb_otg_fs_dp_pa12' defined in modules/hal/stm32/dts/st/f4/stm32f429zitx-pinctrl.dtsi:2607 */
			usb_otg_fs_dp_pa12: usb_otg_fs_dp_pa12 {
				pinmux = < 0x18a >; /* in modules/hal/stm32/dts/st/f4/stm32f429zitx-pinctrl.dtsi:2608 */
				phandle = < 0x11 >; /* in zephyr/boards/st/nucleo_f429zi/nucleo_f429zi.dts:148 */
			};
		};

		/* node '/soc/watchdog@40003000' defined in zephyr/dts/arm/st/f4/stm32f4.dtsi:227 */
		iwdg: watchdog@40003000 {
			compatible = "st,stm32-watchdog"; /* in zephyr/dts/arm/st/f4/stm32f4.dtsi:228 */
			reg = < 0x40003000 0x400 >;       /* in zephyr/dts/arm/st/f4/stm32f4.dtsi:229 */
			status = "okay";                  /* in zephyr/boards/st/nucleo_f429zi/nucleo_f429zi.dts:171 */
		};

		/* node '/soc/watchdog@40002c00' defined in zephyr/dts/arm/st/f4/stm32f4.dtsi:233 */
		wwdg: watchdog@40002c00 {
			compatible = "st,stm32-window-watchdog"; /* in zephyr/dts/arm/st/f4/stm32f4.dtsi:234 */
			reg = < 0x40002c00 0x400 >;              /* in zephyr/dts/arm/st/f4/stm32f4.dtsi:235 */
			clocks = < &rcc 0x40 0x800 >;            /* in zephyr/dts/arm/st/f4/stm32f4.dtsi:236 */
			interrupts = < 0x0 0x7 >;                /* in zephyr/dts/arm/st/f4/stm32f4.dtsi:237 */
			status = "disabled";                     /* in zephyr/dts/arm/st/f4/stm32f4.dtsi:238 */
		};

		/* node '/soc/serial@40011000' defined in zephyr/dts/arm/st/f4/stm32f4.dtsi:241 */
		usart1: serial@40011000 {
			compatible = "st,stm32-usart",
			             "st,stm32-uart";  /* in zephyr/dts/arm/st/f4/stm32f4.dtsi:242 */
			reg = < 0x40011000 0x400 >;    /* in zephyr/dts/arm/st/f4/stm32f4.dtsi:243 */
			clocks = < &rcc 0x44 0x10 >;   /* in zephyr/dts/arm/st/f4/stm32f4.dtsi:244 */
			resets = < &rctl 0x484 >;      /* in zephyr/dts/arm/st/f4/stm32f4.dtsi:245 */
			interrupts = < 0x25 0x0 >;     /* in zephyr/dts/arm/st/f4/stm32f4.dtsi:246 */
			status = "disabled";           /* in zephyr/dts/arm/st/f4/stm32f4.dtsi:247 */
		};

		/* node '/soc/serial@40004400' defined in zephyr/dts/arm/st/f4/stm32f4.dtsi:250 */
		usart2: serial@40004400 {
			compatible = "st,stm32-usart",
			             "st,stm32-uart";   /* in zephyr/dts/arm/st/f4/stm32f4.dtsi:251 */
			reg = < 0x40004400 0x400 >;     /* in zephyr/dts/arm/st/f4/stm32f4.dtsi:252 */
			clocks = < &rcc 0x40 0x20000 >; /* in zephyr/dts/arm/st/f4/stm32f4.dtsi:253 */
			resets = < &rctl 0x411 >;       /* in zephyr/dts/arm/st/f4/stm32f4.dtsi:254 */
			interrupts = < 0x26 0x0 >;      /* in zephyr/dts/arm/st/f4/stm32f4.dtsi:255 */
			status = "disabled";            /* in zephyr/dts/arm/st/f4/stm32f4.dtsi:256 */
		};

		/* node '/soc/serial@40011400' defined in zephyr/dts/arm/st/f4/stm32f4.dtsi:259 */
		usart6: arduino_serial: serial@40011400 {
			compatible = "st,stm32-usart",
			             "st,stm32-uart";                   /* in zephyr/dts/arm/st/f4/stm32f4.dtsi:260 */
			reg = < 0x40011400 0x400 >;                     /* in zephyr/dts/arm/st/f4/stm32f4.dtsi:261 */
			clocks = < &rcc 0x44 0x20 >;                    /* in zephyr/dts/arm/st/f4/stm32f4.dtsi:262 */
			resets = < &rctl 0x485 >;                       /* in zephyr/dts/arm/st/f4/stm32f4.dtsi:263 */
			interrupts = < 0x47 0x0 >;                      /* in zephyr/dts/arm/st/f4/stm32f4.dtsi:264 */
			pinctrl-0 = < &usart6_tx_pg14 &usart6_rx_pg9 >; /* in zephyr/boards/st/nucleo_f429zi/nucleo_f429zi.dts:141 */
			pinctrl-names = "default";                      /* in zephyr/boards/st/nucleo_f429zi/nucleo_f429zi.dts:142 */
			current-speed = < 0x1c200 >;                    /* in zephyr/boards/st/nucleo_f429zi/nucleo_f429zi.dts:143 */
			status = "okay";                                /* in zephyr/boards/st/nucleo_f429zi/nucleo_f429zi.dts:144 */
		};

		/* node '/soc/i2c@40005400' defined in zephyr/dts/arm/st/f4/stm32f4.dtsi:268 */
		i2c1: arduino_i2c: i2c@40005400 {
			compatible = "st,stm32-i2c-v1";              /* in zephyr/dts/arm/st/f4/stm32f4.dtsi:269 */
			#address-cells = < 0x1 >;                    /* in zephyr/dts/arm/st/f4/stm32f4.dtsi:271 */
			#size-cells = < 0x0 >;                       /* in zephyr/dts/arm/st/f4/stm32f4.dtsi:272 */
			reg = < 0x40005400 0x400 >;                  /* in zephyr/dts/arm/st/f4/stm32f4.dtsi:273 */
			clocks = < &rcc 0x40 0x200000 >;             /* in zephyr/dts/arm/st/f4/stm32f4.dtsi:274 */
			interrupts = < 0x1f 0x0 >,
			             < 0x20 0x0 >;                   /* in zephyr/dts/arm/st/f4/stm32f4.dtsi:275 */
			interrupt-names = "event",
			                  "error";                   /* in zephyr/dts/arm/st/f4/stm32f4.dtsi:276 */
			pinctrl-0 = < &i2c1_scl_pb8 &i2c1_sda_pb9 >; /* in zephyr/boards/st/nucleo_f429zi/nucleo_f429zi.dts:113 */
			pinctrl-names = "default";                   /* in zephyr/boards/st/nucleo_f429zi/nucleo_f429zi.dts:114 */
			status = "okay";                             /* in zephyr/boards/st/nucleo_f429zi/nucleo_f429zi.dts:115 */
			clock-frequency = < 0x61a80 >;               /* in zephyr/boards/st/nucleo_f429zi/nucleo_f429zi.dts:116 */
			phandle = < 0x28 >;                          /* in zephyr/dts/arm/st/f4/stm32f4.dtsi:654 */
		};

		/* node '/soc/i2c@40005800' defined in zephyr/dts/arm/st/f4/stm32f4.dtsi:280 */
		i2c2: i2c@40005800 {
			compatible = "st,stm32-i2c-v1";                /* in zephyr/dts/arm/st/f4/stm32f4.dtsi:281 */
			#address-cells = < 0x1 >;                      /* in zephyr/dts/arm/st/f4/stm32f4.dtsi:283 */
			#size-cells = < 0x0 >;                         /* in zephyr/dts/arm/st/f4/stm32f4.dtsi:284 */
			reg = < 0x40005800 0x400 >;                    /* in zephyr/dts/arm/st/f4/stm32f4.dtsi:285 */
			clocks = < &rcc 0x40 0x400000 >;               /* in zephyr/dts/arm/st/f4/stm32f4.dtsi:286 */
			interrupts = < 0x21 0x0 >,
			             < 0x22 0x0 >;                     /* in zephyr/dts/arm/st/f4/stm32f4.dtsi:287 */
			interrupt-names = "event",
			                  "error";                     /* in zephyr/dts/arm/st/f4/stm32f4.dtsi:288 */
			pinctrl-0 = < &i2c2_scl_pb10 &i2c2_sda_pb11 >; /* in zephyr/boards/st/nucleo_f429zi/nucleo_f429zi.dts:120 */
			pinctrl-names = "default";                     /* in zephyr/boards/st/nucleo_f429zi/nucleo_f429zi.dts:121 */
			status = "okay";                               /* in zephyr/boards/st/nucleo_f429zi/nucleo_f429zi.dts:122 */
			clock-frequency = < 0x61a80 >;                 /* in zephyr/boards/st/nucleo_f429zi/nucleo_f429zi.dts:123 */
			phandle = < 0x29 >;                            /* in zephyr/dts/arm/st/f4/stm32f4.dtsi:662 */
		};

		/* node '/soc/i2c@40005c00' defined in zephyr/dts/arm/st/f4/stm32f4.dtsi:292 */
		i2c3: i2c@40005c00 {
			compatible = "st,stm32-i2c-v1";  /* in zephyr/dts/arm/st/f4/stm32f4.dtsi:293 */
			clock-frequency = < 0x186a0 >;   /* in zephyr/dts/arm/st/f4/stm32f4.dtsi:294 */
			#address-cells = < 0x1 >;        /* in zephyr/dts/arm/st/f4/stm32f4.dtsi:295 */
			#size-cells = < 0x0 >;           /* in zephyr/dts/arm/st/f4/stm32f4.dtsi:296 */
			reg = < 0x40005c00 0x400 >;      /* in zephyr/dts/arm/st/f4/stm32f4.dtsi:297 */
			clocks = < &rcc 0x40 0x800000 >; /* in zephyr/dts/arm/st/f4/stm32f4.dtsi:298 */
			interrupts = < 0x48 0x0 >,
			             < 0x49 0x0 >;       /* in zephyr/dts/arm/st/f4/stm32f4.dtsi:299 */
			interrupt-names = "event",
			                  "error";       /* in zephyr/dts/arm/st/f4/stm32f4.dtsi:300 */
			status = "disabled";             /* in zephyr/dts/arm/st/f4/stm32f4.dtsi:301 */
			phandle = < 0x2a >;              /* in zephyr/dts/arm/st/f4/stm32f4.dtsi:670 */
		};

		/* node '/soc/spi@40013000' defined in zephyr/dts/arm/st/f4/stm32f4.dtsi:304 */
		spi1: arduino_spi: spi@40013000 {
			compatible = "st,stm32-spi";                                 /* in zephyr/dts/arm/st/f4/stm32f4.dtsi:305 */
			#address-cells = < 0x1 >;                                    /* in zephyr/dts/arm/st/f4/stm32f4.dtsi:306 */
			#size-cells = < 0x0 >;                                       /* in zephyr/dts/arm/st/f4/stm32f4.dtsi:307 */
			reg = < 0x40013000 0x400 >;                                  /* in zephyr/dts/arm/st/f4/stm32f4.dtsi:308 */
			clocks = < &rcc 0x44 0x1000 >;                               /* in zephyr/dts/arm/st/f4/stm32f4.dtsi:309 */
			interrupts = < 0x23 0x5 >;                                   /* in zephyr/dts/arm/st/f4/stm32f4.dtsi:310 */
			pinctrl-0 = < &spi1_sck_pa5 &spi1_miso_pa6 &spi1_mosi_pa7 >; /* in zephyr/boards/st/nucleo_f429zi/nucleo_f429zi.dts:127 */
			pinctrl-names = "default";                                   /* in zephyr/boards/st/nucleo_f429zi/nucleo_f429zi.dts:128 */
			cs-gpios = < &gpiod 0xe 0x11 >;                              /* in zephyr/boards/st/nucleo_f429zi/nucleo_f429zi.dts:129 */
			status = "okay";                                             /* in zephyr/boards/st/nucleo_f429zi/nucleo_f429zi.dts:130 */
		};

		/* node '/soc/usb@50000000' defined in zephyr/dts/arm/st/f4/stm32f4.dtsi:314 */
		usbotg_fs: zephyr_udc0: usb@50000000 {
			compatible = "st,stm32-otgfs";                           /* in zephyr/dts/arm/st/f4/stm32f4.dtsi:315 */
			reg = < 0x50000000 0x40000 >;                            /* in zephyr/dts/arm/st/f4/stm32f4.dtsi:316 */
			interrupts = < 0x43 0x0 >;                               /* in zephyr/dts/arm/st/f4/stm32f4.dtsi:317 */
			interrupt-names = "otgfs";                               /* in zephyr/dts/arm/st/f4/stm32f4.dtsi:318 */
			num-bidir-endpoints = < 0x4 >;                           /* in zephyr/dts/arm/st/f4/stm32f4.dtsi:319 */
			ram-size = < 0x500 >;                                    /* in zephyr/dts/arm/st/f4/stm32f4.dtsi:320 */
			maximum-speed = "full-speed";                            /* in zephyr/dts/arm/st/f4/stm32f4.dtsi:321 */
			phys = < &otgfs_phy >;                                   /* in zephyr/dts/arm/st/f4/stm32f4.dtsi:322 */
			clocks = < &rcc 0x34 0x80 >,
			         < &rcc 0x7 0xff >;                              /* in zephyr/dts/arm/st/f4/stm32f4.dtsi:323 */
			pinctrl-0 = < &usb_otg_fs_dm_pa11 &usb_otg_fs_dp_pa12 >; /* in zephyr/boards/st/nucleo_f429zi/nucleo_f429zi.dts:148 */
			pinctrl-names = "default";                               /* in zephyr/boards/st/nucleo_f429zi/nucleo_f429zi.dts:149 */
			status = "okay";                                         /* in zephyr/boards/st/nucleo_f429zi/nucleo_f429zi.dts:150 */
		};

		/* node '/soc/timers@40010000' defined in zephyr/dts/arm/st/f4/stm32f4.dtsi:328 */
		timers1: timers@40010000 {
			compatible = "st,stm32-timers"; /* in zephyr/dts/arm/st/f4/stm32f4.dtsi:329 */
			reg = < 0x40010000 0x400 >;     /* in zephyr/dts/arm/st/f4/stm32f4.dtsi:330 */
			clocks = < &rcc 0x44 0x1 >,
			         < &rcc 0xd 0xff >;     /* in zephyr/dts/arm/st/f4/stm32f4.dtsi:331 */
			resets = < &rctl 0x480 >;       /* in zephyr/dts/arm/st/f4/stm32f4.dtsi:333 */
			interrupts = < 0x18 0x0 >,
			             < 0x19 0x0 >,
			             < 0x1a 0x0 >,
			             < 0x1b 0x0 >;      /* in zephyr/dts/arm/st/f4/stm32f4.dtsi:334 */
			interrupt-names = "brk",
			                  "up",
			                  "trgcom",
			                  "cc";         /* in zephyr/dts/arm/st/f4/stm32f4.dtsi:335 */
			st,prescaler = < 0x2710 >;      /* in zephyr/boards/st/nucleo_f429zi/nucleo_f429zi.dts:154 */
			status = "okay";                /* in zephyr/boards/st/nucleo_f429zi/nucleo_f429zi.dts:155 */

			/* node '/soc/timers@40010000/pwm' defined in zephyr/dts/arm/st/f4/stm32f4.dtsi:339 */
			pwm1: pwm {
				compatible = "st,stm32-pwm";    /* in zephyr/dts/arm/st/f4/stm32f4.dtsi:340 */
				#pwm-cells = < 0x3 >;           /* in zephyr/dts/arm/st/f4/stm32f4.dtsi:342 */
				status = "okay";                /* in zephyr/boards/st/nucleo_f429zi/nucleo_f429zi.dts:158 */
				pinctrl-0 = < &tim1_ch3_pe13 >; /* in zephyr/boards/st/nucleo_f429zi/nucleo_f429zi.dts:159 */
				pinctrl-names = "default";      /* in zephyr/boards/st/nucleo_f429zi/nucleo_f429zi.dts:160 */
			};

			/* node '/soc/timers@40010000/qdec' defined in zephyr/dts/arm/st/f4/stm32f4.dtsi:345 */
			qdec {
				compatible = "st,stm32-qdec";    /* in zephyr/dts/arm/st/f4/stm32f4.dtsi:346 */
				st,input-filter-level = < 0x0 >; /* in zephyr/dts/arm/st/f4/stm32f4.dtsi:347 */
				status = "disabled";             /* in zephyr/dts/arm/st/f4/stm32f4.dtsi:348 */
			};
		};

		/* node '/soc/timers@40000000' defined in zephyr/dts/arm/st/f4/stm32f4.dtsi:352 */
		timers2: timers@40000000 {
			compatible = "st,stm32-timers"; /* in zephyr/dts/arm/st/f4/stm32f4.dtsi:353 */
			reg = < 0x40000000 0x400 >;     /* in zephyr/dts/arm/st/f4/stm32f4.dtsi:354 */
			clocks = < &rcc 0x40 0x1 >,
			         < &rcc 0xc 0xff >;     /* in zephyr/dts/arm/st/f4/stm32f4.dtsi:355 */
			resets = < &rctl 0x400 >;       /* in zephyr/dts/arm/st/f4/stm32f4.dtsi:357 */
			interrupts = < 0x1c 0x0 >;      /* in zephyr/dts/arm/st/f4/stm32f4.dtsi:358 */
			interrupt-names = "global";     /* in zephyr/dts/arm/st/f4/stm32f4.dtsi:359 */
			st,prescaler = < 0x0 >;         /* in zephyr/dts/arm/st/f4/stm32f4.dtsi:360 */
			status = "disabled";            /* in zephyr/dts/arm/st/f4/stm32f4.dtsi:361 */

			/* node '/soc/timers@40000000/pwm' defined in zephyr/dts/arm/st/f4/stm32f4.dtsi:363 */
			pwm {
				compatible = "st,stm32-pwm"; /* in zephyr/dts/arm/st/f4/stm32f4.dtsi:364 */
				status = "disabled";         /* in zephyr/dts/arm/st/f4/stm32f4.dtsi:365 */
				#pwm-cells = < 0x3 >;        /* in zephyr/dts/arm/st/f4/stm32f4.dtsi:366 */
			};

			/* node '/soc/timers@40000000/counter' defined in zephyr/dts/arm/st/f4/stm32f4.dtsi:369 */
			counter {
				compatible = "st,stm32-counter"; /* in zephyr/dts/arm/st/f4/stm32f4.dtsi:370 */
				status = "disabled";             /* in zephyr/dts/arm/st/f4/stm32f4.dtsi:371 */
			};

			/* node '/soc/timers@40000000/qdec' defined in zephyr/dts/arm/st/f4/stm32f4.dtsi:374 */
			qdec {
				compatible = "st,stm32-qdec";    /* in zephyr/dts/arm/st/f4/stm32f4.dtsi:375 */
				st,input-filter-level = < 0x0 >; /* in zephyr/dts/arm/st/f4/stm32f4.dtsi:376 */
				status = "disabled";             /* in zephyr/dts/arm/st/f4/stm32f4.dtsi:377 */
			};
		};

		/* node '/soc/timers@40000400' defined in zephyr/dts/arm/st/f4/stm32f4.dtsi:381 */
		timers3: timers@40000400 {
			compatible = "st,stm32-timers"; /* in zephyr/dts/arm/st/f4/stm32f4.dtsi:382 */
			reg = < 0x40000400 0x400 >;     /* in zephyr/dts/arm/st/f4/stm32f4.dtsi:383 */
			clocks = < &rcc 0x40 0x2 >,
			         < &rcc 0xc 0xff >;     /* in zephyr/dts/arm/st/f4/stm32f4.dtsi:384 */
			resets = < &rctl 0x401 >;       /* in zephyr/dts/arm/st/f4/stm32f4.dtsi:386 */
			interrupts = < 0x1d 0x0 >;      /* in zephyr/dts/arm/st/f4/stm32f4.dtsi:387 */
			interrupt-names = "global";     /* in zephyr/dts/arm/st/f4/stm32f4.dtsi:388 */
			st,prescaler = < 0x0 >;         /* in zephyr/dts/arm/st/f4/stm32f4.dtsi:389 */
			status = "disabled";            /* in zephyr/dts/arm/st/f4/stm32f4.dtsi:390 */

			/* node '/soc/timers@40000400/pwm' defined in zephyr/dts/arm/st/f4/stm32f4.dtsi:392 */
			pwm {
				compatible = "st,stm32-pwm"; /* in zephyr/dts/arm/st/f4/stm32f4.dtsi:393 */
				status = "disabled";         /* in zephyr/dts/arm/st/f4/stm32f4.dtsi:394 */
				#pwm-cells = < 0x3 >;        /* in zephyr/dts/arm/st/f4/stm32f4.dtsi:395 */
			};

			/* node '/soc/timers@40000400/counter' defined in zephyr/dts/arm/st/f4/stm32f4.dtsi:398 */
			counter {
				compatible = "st,stm32-counter"; /* in zephyr/dts/arm/st/f4/stm32f4.dtsi:399 */
				status = "disabled";             /* in zephyr/dts/arm/st/f4/stm32f4.dtsi:400 */
			};

			/* node '/soc/timers@40000400/qdec' defined in zephyr/dts/arm/st/f4/stm32f4.dtsi:403 */
			qdec {
				compatible = "st,stm32-qdec";    /* in zephyr/dts/arm/st/f4/stm32f4.dtsi:404 */
				st,input-filter-level = < 0x0 >; /* in zephyr/dts/arm/st/f4/stm32f4.dtsi:405 */
				status = "disabled";             /* in zephyr/dts/arm/st/f4/stm32f4.dtsi:406 */
			};
		};

		/* node '/soc/timers@40000800' defined in zephyr/dts/arm/st/f4/stm32f4.dtsi:410 */
		timers4: timers@40000800 {
			compatible = "st,stm32-timers"; /* in zephyr/dts/arm/st/f4/stm32f4.dtsi:411 */
			reg = < 0x40000800 0x400 >;     /* in zephyr/dts/arm/st/f4/stm32f4.dtsi:412 */
			clocks = < &rcc 0x40 0x4 >,
			         < &rcc 0xc 0xff >;     /* in zephyr/dts/arm/st/f4/stm32f4.dtsi:413 */
			resets = < &rctl 0x402 >;       /* in zephyr/dts/arm/st/f4/stm32f4.dtsi:415 */
			interrupts = < 0x1e 0x0 >;      /* in zephyr/dts/arm/st/f4/stm32f4.dtsi:416 */
			interrupt-names = "global";     /* in zephyr/dts/arm/st/f4/stm32f4.dtsi:417 */
			st,prescaler = < 0x0 >;         /* in zephyr/dts/arm/st/f4/stm32f4.dtsi:418 */
			status = "disabled";            /* in zephyr/dts/arm/st/f4/stm32f4.dtsi:419 */

			/* node '/soc/timers@40000800/pwm' defined in zephyr/dts/arm/st/f4/stm32f4.dtsi:421 */
			pwm {
				compatible = "st,stm32-pwm"; /* in zephyr/dts/arm/st/f4/stm32f4.dtsi:422 */
				status = "disabled";         /* in zephyr/dts/arm/st/f4/stm32f4.dtsi:423 */
				#pwm-cells = < 0x3 >;        /* in zephyr/dts/arm/st/f4/stm32f4.dtsi:424 */
			};

			/* node '/soc/timers@40000800/counter' defined in zephyr/dts/arm/st/f4/stm32f4.dtsi:427 */
			counter {
				compatible = "st,stm32-counter"; /* in zephyr/dts/arm/st/f4/stm32f4.dtsi:428 */
				status = "disabled";             /* in zephyr/dts/arm/st/f4/stm32f4.dtsi:429 */
			};

			/* node '/soc/timers@40000800/qdec' defined in zephyr/dts/arm/st/f4/stm32f4.dtsi:432 */
			qdec {
				compatible = "st,stm32-qdec";    /* in zephyr/dts/arm/st/f4/stm32f4.dtsi:433 */
				st,input-filter-level = < 0x0 >; /* in zephyr/dts/arm/st/f4/stm32f4.dtsi:434 */
				status = "disabled";             /* in zephyr/dts/arm/st/f4/stm32f4.dtsi:435 */
			};
		};

		/* node '/soc/timers@40000c00' defined in zephyr/dts/arm/st/f4/stm32f4.dtsi:439 */
		timers5: timers@40000c00 {
			compatible = "st,stm32-timers"; /* in zephyr/dts/arm/st/f4/stm32f4.dtsi:440 */
			reg = < 0x40000c00 0x400 >;     /* in zephyr/dts/arm/st/f4/stm32f4.dtsi:441 */
			clocks = < &rcc 0x40 0x8 >,
			         < &rcc 0xc 0xff >;     /* in zephyr/dts/arm/st/f4/stm32f4.dtsi:442 */
			resets = < &rctl 0x403 >;       /* in zephyr/dts/arm/st/f4/stm32f4.dtsi:444 */
			interrupts = < 0x32 0x0 >;      /* in zephyr/dts/arm/st/f4/stm32f4.dtsi:445 */
			interrupt-names = "global";     /* in zephyr/dts/arm/st/f4/stm32f4.dtsi:446 */
			st,prescaler = < 0x0 >;         /* in zephyr/dts/arm/st/f4/stm32f4.dtsi:447 */
			status = "disabled";            /* in zephyr/dts/arm/st/f4/stm32f4.dtsi:448 */

			/* node '/soc/timers@40000c00/pwm' defined in zephyr/dts/arm/st/f4/stm32f4.dtsi:450 */
			pwm {
				compatible = "st,stm32-pwm"; /* in zephyr/dts/arm/st/f4/stm32f4.dtsi:451 */
				status = "disabled";         /* in zephyr/dts/arm/st/f4/stm32f4.dtsi:452 */
				#pwm-cells = < 0x3 >;        /* in zephyr/dts/arm/st/f4/stm32f4.dtsi:453 */
			};

			/* node '/soc/timers@40000c00/counter' defined in zephyr/dts/arm/st/f4/stm32f4.dtsi:456 */
			counter {
				compatible = "st,stm32-counter"; /* in zephyr/dts/arm/st/f4/stm32f4.dtsi:457 */
				status = "disabled";             /* in zephyr/dts/arm/st/f4/stm32f4.dtsi:458 */
			};

			/* node '/soc/timers@40000c00/qdec' defined in zephyr/dts/arm/st/f4/stm32f4.dtsi:461 */
			qdec {
				compatible = "st,stm32-qdec";    /* in zephyr/dts/arm/st/f4/stm32f4.dtsi:462 */
				st,input-filter-level = < 0x0 >; /* in zephyr/dts/arm/st/f4/stm32f4.dtsi:463 */
				status = "disabled";             /* in zephyr/dts/arm/st/f4/stm32f4.dtsi:464 */
			};
		};

		/* node '/soc/timers@40014000' defined in zephyr/dts/arm/st/f4/stm32f4.dtsi:468 */
		timers9: timers@40014000 {
			compatible = "st,stm32-timers"; /* in zephyr/dts/arm/st/f4/stm32f4.dtsi:469 */
			reg = < 0x40014000 0x400 >;     /* in zephyr/dts/arm/st/f4/stm32f4.dtsi:470 */
			clocks = < &rcc 0x44 0x10000 >,
			         < &rcc 0xd 0xff >;     /* in zephyr/dts/arm/st/f4/stm32f4.dtsi:471 */
			resets = < &rctl 0x490 >;       /* in zephyr/dts/arm/st/f4/stm32f4.dtsi:473 */
			interrupts = < 0x18 0x0 >;      /* in zephyr/dts/arm/st/f4/stm32f4.dtsi:474 */
			interrupt-names = "global";     /* in zephyr/dts/arm/st/f4/stm32f4.dtsi:475 */
			st,prescaler = < 0x0 >;         /* in zephyr/dts/arm/st/f4/stm32f4.dtsi:476 */
			status = "disabled";            /* in zephyr/dts/arm/st/f4/stm32f4.dtsi:477 */

			/* node '/soc/timers@40014000/pwm' defined in zephyr/dts/arm/st/f4/stm32f4.dtsi:479 */
			pwm {
				compatible = "st,stm32-pwm"; /* in zephyr/dts/arm/st/f4/stm32f4.dtsi:480 */
				status = "disabled";         /* in zephyr/dts/arm/st/f4/stm32f4.dtsi:481 */
				#pwm-cells = < 0x3 >;        /* in zephyr/dts/arm/st/f4/stm32f4.dtsi:482 */
			};

			/* node '/soc/timers@40014000/counter' defined in zephyr/dts/arm/st/f4/stm32f4.dtsi:485 */
			counter {
				compatible = "st,stm32-counter"; /* in zephyr/dts/arm/st/f4/stm32f4.dtsi:486 */
				status = "disabled";             /* in zephyr/dts/arm/st/f4/stm32f4.dtsi:487 */
			};
		};

		/* node '/soc/timers@40014400' defined in zephyr/dts/arm/st/f4/stm32f4.dtsi:491 */
		timers10: timers@40014400 {
			compatible = "st,stm32-timers"; /* in zephyr/dts/arm/st/f4/stm32f4.dtsi:492 */
			reg = < 0x40014400 0x400 >;     /* in zephyr/dts/arm/st/f4/stm32f4.dtsi:493 */
			clocks = < &rcc 0x44 0x20000 >,
			         < &rcc 0xd 0xff >;     /* in zephyr/dts/arm/st/f4/stm32f4.dtsi:494 */
			resets = < &rctl 0x491 >;       /* in zephyr/dts/arm/st/f4/stm32f4.dtsi:496 */
			interrupts = < 0x19 0x0 >;      /* in zephyr/dts/arm/st/f4/stm32f4.dtsi:497 */
			interrupt-names = "global";     /* in zephyr/dts/arm/st/f4/stm32f4.dtsi:498 */
			st,prescaler = < 0x0 >;         /* in zephyr/dts/arm/st/f4/stm32f4.dtsi:499 */
			status = "disabled";            /* in zephyr/dts/arm/st/f4/stm32f4.dtsi:500 */

			/* node '/soc/timers@40014400/pwm' defined in zephyr/dts/arm/st/f4/stm32f4.dtsi:502 */
			pwm {
				compatible = "st,stm32-pwm"; /* in zephyr/dts/arm/st/f4/stm32f4.dtsi:503 */
				status = "disabled";         /* in zephyr/dts/arm/st/f4/stm32f4.dtsi:504 */
				#pwm-cells = < 0x3 >;        /* in zephyr/dts/arm/st/f4/stm32f4.dtsi:505 */
			};

			/* node '/soc/timers@40014400/counter' defined in zephyr/dts/arm/st/f4/stm32f4.dtsi:508 */
			counter {
				compatible = "st,stm32-counter"; /* in zephyr/dts/arm/st/f4/stm32f4.dtsi:509 */
				status = "disabled";             /* in zephyr/dts/arm/st/f4/stm32f4.dtsi:510 */
			};
		};

		/* node '/soc/timers@40014800' defined in zephyr/dts/arm/st/f4/stm32f4.dtsi:514 */
		timers11: timers@40014800 {
			compatible = "st,stm32-timers"; /* in zephyr/dts/arm/st/f4/stm32f4.dtsi:515 */
			reg = < 0x40014800 0x400 >;     /* in zephyr/dts/arm/st/f4/stm32f4.dtsi:516 */
			clocks = < &rcc 0x44 0x40000 >,
			         < &rcc 0xd 0xff >;     /* in zephyr/dts/arm/st/f4/stm32f4.dtsi:517 */
			resets = < &rctl 0x492 >;       /* in zephyr/dts/arm/st/f4/stm32f4.dtsi:519 */
			interrupts = < 0x1a 0x0 >;      /* in zephyr/dts/arm/st/f4/stm32f4.dtsi:520 */
			interrupt-names = "global";     /* in zephyr/dts/arm/st/f4/stm32f4.dtsi:521 */
			st,prescaler = < 0x0 >;         /* in zephyr/dts/arm/st/f4/stm32f4.dtsi:522 */
			status = "disabled";            /* in zephyr/dts/arm/st/f4/stm32f4.dtsi:523 */

			/* node '/soc/timers@40014800/pwm' defined in zephyr/dts/arm/st/f4/stm32f4.dtsi:525 */
			pwm {
				compatible = "st,stm32-pwm"; /* in zephyr/dts/arm/st/f4/stm32f4.dtsi:526 */
				status = "disabled";         /* in zephyr/dts/arm/st/f4/stm32f4.dtsi:527 */
				#pwm-cells = < 0x3 >;        /* in zephyr/dts/arm/st/f4/stm32f4.dtsi:528 */
			};

			/* node '/soc/timers@40014800/counter' defined in zephyr/dts/arm/st/f4/stm32f4.dtsi:531 */
			counter {
				compatible = "st,stm32-counter"; /* in zephyr/dts/arm/st/f4/stm32f4.dtsi:532 */
				status = "disabled";             /* in zephyr/dts/arm/st/f4/stm32f4.dtsi:533 */
			};
		};

		/* node '/soc/rtc@40002800' defined in zephyr/dts/arm/st/f4/stm32f4.dtsi:537 */
		rtc: rtc@40002800 {
			compatible = "st,stm32-rtc";       /* in zephyr/dts/arm/st/f4/stm32f4.dtsi:538 */
			reg = < 0x40002800 0x400 >;        /* in zephyr/dts/arm/st/f4/stm32f4.dtsi:539 */
			interrupts = < 0x29 0x0 >;         /* in zephyr/dts/arm/st/f4/stm32f4.dtsi:540 */
			prescaler = < 0x8000 >;            /* in zephyr/dts/arm/st/f4/stm32f4.dtsi:542 */
			alarms-count = < 0x2 >;            /* in zephyr/dts/arm/st/f4/stm32f4.dtsi:543 */
			alrm-exti-line = < 0x11 >;         /* in zephyr/dts/arm/st/f4/stm32f4.dtsi:544 */
			clocks = < &rcc 0x40 0x10000000 >,
			         < &rcc 0x3 0x2280070 >;   /* in zephyr/boards/st/nucleo_f429zi/nucleo_f429zi.dts:165 */
			status = "okay";                   /* in zephyr/boards/st/nucleo_f429zi/nucleo_f429zi.dts:167 */

			/* node '/soc/rtc@40002800/backup_regs' defined in zephyr/dts/arm/st/f4/stm32f4.dtsi:547 */
			bbram: backup_regs {
				compatible = "st,stm32-bbram"; /* in zephyr/dts/arm/st/f4/stm32f4.dtsi:548 */
				st,backup-regs = < 0x14 >;     /* in zephyr/dts/arm/st/f4/stm32f4.dtsi:549 */
				status = "disabled";           /* in zephyr/dts/arm/st/f4/stm32f4.dtsi:550 */
			};
		};

		/* node '/soc/adc@40012000' defined in zephyr/dts/arm/st/f4/stm32f4.dtsi:554 */
		adc1: adc@40012000 {
			compatible = "st,stm32f4-adc",
			             "st,stm32-adc";                                 /* in zephyr/dts/arm/st/f4/stm32f4.dtsi:555 */
			reg = < 0x40012000 0x400 >;                                  /* in zephyr/dts/arm/st/f4/stm32f4.dtsi:556 */
			clocks = < &rcc 0x44 0x100 >;                                /* in zephyr/dts/arm/st/f4/stm32f4.dtsi:557 */
			clock-names = "adcx";                                        /* in zephyr/dts/arm/st/f4/stm32f4.dtsi:558 */
			interrupts = < 0x12 0x0 >;                                   /* in zephyr/dts/arm/st/f4/stm32f4.dtsi:559 */
			#io-channel-cells = < 0x1 >;                                 /* in zephyr/dts/arm/st/f4/stm32f4.dtsi:560 */
			resolutions = < 0x607804 0x517804 0x427804 0x337804 >;       /* in zephyr/dts/arm/st/f4/stm32f4.dtsi:561 */
			sampling-times = < 0x3 0xf 0x1c 0x38 0x54 0x70 0x90 0x1e0 >; /* in zephyr/dts/arm/st/f4/stm32f4.dtsi:565 */
			st,adc-sequencer = "programmable";                           /* in zephyr/dts/arm/st/f4/stm32f4.dtsi:567 */
			st,adc-oversampler = "none";                                 /* in zephyr/dts/arm/st/f4/stm32f4.dtsi:568 */
			st,adc-internal-regulator = "none";                          /* in zephyr/dts/arm/st/f4/stm32f4.dtsi:569 */
			pinctrl-0 = < &adc1_in0_pa0 >;                               /* in zephyr/boards/st/nucleo_f429zi/nucleo_f429zi.dts:95 */
			pinctrl-names = "default";                                   /* in zephyr/boards/st/nucleo_f429zi/nucleo_f429zi.dts:96 */
			st,adc-clock-source = "SYNC";                                /* in zephyr/boards/st/nucleo_f429zi/nucleo_f429zi.dts:97 */
			st,adc-prescaler = < 0x2 >;                                  /* in zephyr/boards/st/nucleo_f429zi/nucleo_f429zi.dts:98 */
			status = "okay";                                             /* in zephyr/boards/st/nucleo_f429zi/nucleo_f429zi.dts:99 */
			phandle = < 0x27 >;                                          /* in zephyr/dts/arm/st/f4/stm32f427.dtsi:140 */
		};

		/* node '/soc/dma@40026000' defined in zephyr/dts/arm/st/f4/stm32f4.dtsi:573 */
		dma1: dma@40026000 {
			compatible = "st,stm32-dma-v1";                                                      /* in zephyr/dts/arm/st/f4/stm32f4.dtsi:574 */
			#dma-cells = < 0x4 >;                                                                /* in zephyr/dts/arm/st/f4/stm32f4.dtsi:575 */
			reg = < 0x40026000 0x400 >;                                                          /* in zephyr/dts/arm/st/f4/stm32f4.dtsi:576 */
			interrupts = < 0xb 0x0 0xc 0x0 0xd 0x0 0xe 0x0 0xf 0x0 0x10 0x0 0x11 0x0 0x2f 0x0 >; /* in zephyr/dts/arm/st/f4/stm32f4.dtsi:577 */
			clocks = < &rcc 0x30 0x200000 >;                                                     /* in zephyr/dts/arm/st/f4/stm32f4.dtsi:578 */
			status = "disabled";                                                                 /* in zephyr/dts/arm/st/f4/stm32f4.dtsi:579 */
			phandle = < 0x14 >;                                                                  /* in zephyr/dts/arm/st/f4/stm32f401.dtsi:58 */
		};

		/* node '/soc/dma@40026400' defined in zephyr/dts/arm/st/f4/stm32f4.dtsi:582 */
		dma2: dma@40026400 {
			compatible = "st,stm32-dma-v1";                                                           /* in zephyr/dts/arm/st/f4/stm32f4.dtsi:583 */
			#dma-cells = < 0x4 >;                                                                     /* in zephyr/dts/arm/st/f4/stm32f4.dtsi:584 */
			reg = < 0x40026400 0x400 >;                                                               /* in zephyr/dts/arm/st/f4/stm32f4.dtsi:585 */
			interrupts = < 0x38 0x0 0x39 0x0 0x3a 0x0 0x3b 0x0 0x3c 0x0 0x44 0x0 0x45 0x0 0x46 0x0 >; /* in zephyr/dts/arm/st/f4/stm32f4.dtsi:586 */
			clocks = < &rcc 0x30 0x400000 >;                                                          /* in zephyr/dts/arm/st/f4/stm32f4.dtsi:587 */
			st,mem2mem;                                                                               /* in zephyr/dts/arm/st/f4/stm32f4.dtsi:588 */
			status = "okay";                                                                          /* in zephyr/boards/st/nucleo_f429zi/nucleo_f429zi.dts:179 */
			phandle = < 0x23 >;                                                                       /* in zephyr/dts/arm/st/f4/stm32f427.dtsi:122 */
		};

		/* node '/soc/sdmmc@40012c00' defined in zephyr/dts/arm/st/f4/stm32f4.dtsi:592 */
		sdmmc1: sdmmc@40012c00 {
			compatible = "st,stm32-sdmmc"; /* in zephyr/dts/arm/st/f4/stm32f4.dtsi:593 */
			reg = < 0x40012c00 0x400 >;    /* in zephyr/dts/arm/st/f4/stm32f4.dtsi:594 */
			clocks = < &rcc 0x44 0x800 >,
			         < &rcc 0x7 0xff >;    /* in zephyr/dts/arm/st/f4/stm32f4.dtsi:595 */
			resets = < &rctl 0x48b >;      /* in zephyr/dts/arm/st/f4/stm32f4.dtsi:597 */
			interrupts = < 0x31 0x0 >;     /* in zephyr/dts/arm/st/f4/stm32f4.dtsi:598 */
			status = "disabled";           /* in zephyr/dts/arm/st/f4/stm32f4.dtsi:599 */
		};

		/* node '/soc/spi@40003800' defined in zephyr/dts/arm/st/f4/stm32f401.dtsi:21 */
		spi2: spi@40003800 {
			compatible = "st,stm32-spi";   /* in zephyr/dts/arm/st/f4/stm32f401.dtsi:22 */
			#address-cells = < 0x1 >;      /* in zephyr/dts/arm/st/f4/stm32f401.dtsi:23 */
			#size-cells = < 0x0 >;         /* in zephyr/dts/arm/st/f4/stm32f401.dtsi:24 */
			reg = < 0x40003800 0x400 >;    /* in zephyr/dts/arm/st/f4/stm32f401.dtsi:25 */
			clocks = < &rcc 0x40 0x4000 >; /* in zephyr/dts/arm/st/f4/stm32f401.dtsi:26 */
			interrupts = < 0x24 0x5 >;     /* in zephyr/dts/arm/st/f4/stm32f401.dtsi:27 */
			status = "disabled";           /* in zephyr/dts/arm/st/f4/stm32f401.dtsi:28 */
		};

		/* node '/soc/spi@40003c00' defined in zephyr/dts/arm/st/f4/stm32f401.dtsi:31 */
		spi3: spi@40003c00 {
			compatible = "st,stm32-spi";   /* in zephyr/dts/arm/st/f4/stm32f401.dtsi:32 */
			#address-cells = < 0x1 >;      /* in zephyr/dts/arm/st/f4/stm32f401.dtsi:33 */
			#size-cells = < 0x0 >;         /* in zephyr/dts/arm/st/f4/stm32f401.dtsi:34 */
			reg = < 0x40003c00 0x400 >;    /* in zephyr/dts/arm/st/f4/stm32f401.dtsi:35 */
			clocks = < &rcc 0x40 0x8000 >; /* in zephyr/dts/arm/st/f4/stm32f401.dtsi:36 */
			interrupts = < 0x33 0x5 >;     /* in zephyr/dts/arm/st/f4/stm32f401.dtsi:37 */
			status = "disabled";           /* in zephyr/dts/arm/st/f4/stm32f401.dtsi:38 */
		};

		/* node '/soc/spi@40013400' defined in zephyr/dts/arm/st/f4/stm32f401.dtsi:41 */
		spi4: spi@40013400 {
			compatible = "st,stm32-spi";   /* in zephyr/dts/arm/st/f4/stm32f427.dtsi:67 */
			#address-cells = < 0x1 >;      /* in zephyr/dts/arm/st/f4/stm32f427.dtsi:68 */
			#size-cells = < 0x0 >;         /* in zephyr/dts/arm/st/f4/stm32f427.dtsi:69 */
			reg = < 0x40013400 0x400 >;    /* in zephyr/dts/arm/st/f4/stm32f427.dtsi:70 */
			clocks = < &rcc 0x44 0x2000 >; /* in zephyr/dts/arm/st/f4/stm32f427.dtsi:71 */
			interrupts = < 0x54 0x5 >;     /* in zephyr/dts/arm/st/f4/stm32f427.dtsi:72 */
			status = "disabled";           /* in zephyr/dts/arm/st/f4/stm32f427.dtsi:73 */
		};

		/* node '/soc/i2s@40003800' defined in zephyr/dts/arm/st/f4/stm32f401.dtsi:51 */
		i2s2: i2s@40003800 {
			compatible = "st,stm32-i2s";        /* in zephyr/dts/arm/st/f4/stm32f401.dtsi:52 */
			#address-cells = < 0x1 >;           /* in zephyr/dts/arm/st/f4/stm32f401.dtsi:53 */
			#size-cells = < 0x0 >;              /* in zephyr/dts/arm/st/f4/stm32f401.dtsi:54 */
			reg = < 0x40003800 0x400 >;         /* in zephyr/dts/arm/st/f4/stm32f401.dtsi:55 */
			clocks = < &rcc 0x40 0x4000 >;      /* in zephyr/dts/arm/st/f4/stm32f401.dtsi:56 */
			interrupts = < 0x24 0x5 >;          /* in zephyr/dts/arm/st/f4/stm32f401.dtsi:57 */
			dmas = < &dma1 0x4 0x0 0x400 0x3 >,
			       < &dma1 0x3 0x0 0x400 0x3 >; /* in zephyr/dts/arm/st/f4/stm32f401.dtsi:58 */
			dma-names = "tx",
			            "rx";                   /* in zephyr/dts/arm/st/f4/stm32f401.dtsi:60 */
			status = "disabled";                /* in zephyr/dts/arm/st/f4/stm32f401.dtsi:61 */
		};

		/* node '/soc/i2s@40003c00' defined in zephyr/dts/arm/st/f4/stm32f401.dtsi:64 */
		i2s3: i2s@40003c00 {
			compatible = "st,stm32-i2s";        /* in zephyr/dts/arm/st/f4/stm32f401.dtsi:65 */
			#address-cells = < 0x1 >;           /* in zephyr/dts/arm/st/f4/stm32f401.dtsi:66 */
			#size-cells = < 0x0 >;              /* in zephyr/dts/arm/st/f4/stm32f401.dtsi:67 */
			reg = < 0x40003c00 0x400 >;         /* in zephyr/dts/arm/st/f4/stm32f401.dtsi:68 */
			clocks = < &rcc 0x40 0x8000 >;      /* in zephyr/dts/arm/st/f4/stm32f401.dtsi:69 */
			interrupts = < 0x33 0x5 >;          /* in zephyr/dts/arm/st/f4/stm32f401.dtsi:70 */
			dmas = < &dma1 0x5 0x0 0x400 0x3 >,
			       < &dma1 0x0 0x0 0x400 0x3 >; /* in zephyr/dts/arm/st/f4/stm32f401.dtsi:71 */
			dma-names = "tx",
			            "rx";                   /* in zephyr/dts/arm/st/f4/stm32f401.dtsi:73 */
			status = "disabled";                /* in zephyr/dts/arm/st/f4/stm32f401.dtsi:74 */
		};

		/* node '/soc/serial@40004800' defined in zephyr/dts/arm/st/f4/stm32f405.dtsi:51 */
		usart3: serial@40004800 {
			compatible = "st,stm32-usart",
			             "st,stm32-uart";                  /* in zephyr/dts/arm/st/f4/stm32f405.dtsi:52 */
			reg = < 0x40004800 0x400 >;                    /* in zephyr/dts/arm/st/f4/stm32f405.dtsi:53 */
			clocks = < &rcc 0x40 0x40000 >;                /* in zephyr/dts/arm/st/f4/stm32f405.dtsi:54 */
			resets = < &rctl 0x412 >;                      /* in zephyr/dts/arm/st/f4/stm32f405.dtsi:55 */
			interrupts = < 0x27 0x0 >;                     /* in zephyr/dts/arm/st/f4/stm32f405.dtsi:56 */
			pinctrl-0 = < &usart3_tx_pd8 &usart3_rx_pd9 >; /* in zephyr/boards/st/nucleo_f429zi/nucleo_f429zi.dts:134 */
			pinctrl-names = "default";                     /* in zephyr/boards/st/nucleo_f429zi/nucleo_f429zi.dts:135 */
			current-speed = < 0x1c200 >;                   /* in zephyr/boards/st/nucleo_f429zi/nucleo_f429zi.dts:136 */
			status = "okay";                               /* in zephyr/boards/st/nucleo_f429zi/nucleo_f429zi.dts:137 */
		};

		/* node '/soc/serial@40004c00' defined in zephyr/dts/arm/st/f4/stm32f405.dtsi:60 */
		uart4: serial@40004c00 {
			compatible = "st,stm32-uart";   /* in zephyr/dts/arm/st/f4/stm32f405.dtsi:61 */
			reg = < 0x40004c00 0x400 >;     /* in zephyr/dts/arm/st/f4/stm32f405.dtsi:62 */
			clocks = < &rcc 0x40 0x80000 >; /* in zephyr/dts/arm/st/f4/stm32f405.dtsi:63 */
			resets = < &rctl 0x413 >;       /* in zephyr/dts/arm/st/f4/stm32f405.dtsi:64 */
			interrupts = < 0x34 0x0 >;      /* in zephyr/dts/arm/st/f4/stm32f405.dtsi:65 */
			status = "disabled";            /* in zephyr/dts/arm/st/f4/stm32f405.dtsi:66 */
		};

		/* node '/soc/serial@40005000' defined in zephyr/dts/arm/st/f4/stm32f405.dtsi:69 */
		uart5: serial@40005000 {
			compatible = "st,stm32-uart";    /* in zephyr/dts/arm/st/f4/stm32f405.dtsi:70 */
			reg = < 0x40005000 0x400 >;      /* in zephyr/dts/arm/st/f4/stm32f405.dtsi:71 */
			clocks = < &rcc 0x40 0x100000 >; /* in zephyr/dts/arm/st/f4/stm32f405.dtsi:72 */
			resets = < &rctl 0x414 >;        /* in zephyr/dts/arm/st/f4/stm32f405.dtsi:73 */
			interrupts = < 0x35 0x0 >;       /* in zephyr/dts/arm/st/f4/stm32f405.dtsi:74 */
			status = "disabled";             /* in zephyr/dts/arm/st/f4/stm32f405.dtsi:75 */
		};

		/* node '/soc/timers@40001000' defined in zephyr/dts/arm/st/f4/stm32f405.dtsi:78 */
		timers6: timers@40001000 {
			compatible = "st,stm32-timers"; /* in zephyr/dts/arm/st/f4/stm32f405.dtsi:79 */
			reg = < 0x40001000 0x400 >;     /* in zephyr/dts/arm/st/f4/stm32f405.dtsi:80 */
			clocks = < &rcc 0x40 0x10 >,
			         < &rcc 0xc 0xff >;     /* in zephyr/dts/arm/st/f4/stm32f405.dtsi:81 */
			resets = < &rctl 0x404 >;       /* in zephyr/dts/arm/st/f4/stm32f405.dtsi:83 */
			interrupts = < 0x36 0x0 >;      /* in zephyr/dts/arm/st/f4/stm32f405.dtsi:84 */
			interrupt-names = "global";     /* in zephyr/dts/arm/st/f4/stm32f405.dtsi:85 */
			st,prescaler = < 0x0 >;         /* in zephyr/dts/arm/st/f4/stm32f405.dtsi:86 */
			status = "disabled";            /* in zephyr/dts/arm/st/f4/stm32f405.dtsi:87 */

			/* node '/soc/timers@40001000/counter' defined in zephyr/dts/arm/st/f4/stm32f405.dtsi:89 */
			counter {
				compatible = "st,stm32-counter"; /* in zephyr/dts/arm/st/f4/stm32f405.dtsi:90 */
				status = "disabled";             /* in zephyr/dts/arm/st/f4/stm32f405.dtsi:91 */
			};
		};

		/* node '/soc/timers@40001400' defined in zephyr/dts/arm/st/f4/stm32f405.dtsi:95 */
		timers7: timers@40001400 {
			compatible = "st,stm32-timers"; /* in zephyr/dts/arm/st/f4/stm32f405.dtsi:96 */
			reg = < 0x40001400 0x400 >;     /* in zephyr/dts/arm/st/f4/stm32f405.dtsi:97 */
			clocks = < &rcc 0x40 0x20 >,
			         < &rcc 0xc 0xff >;     /* in zephyr/dts/arm/st/f4/stm32f405.dtsi:98 */
			resets = < &rctl 0x405 >;       /* in zephyr/dts/arm/st/f4/stm32f405.dtsi:100 */
			interrupts = < 0x37 0x0 >;      /* in zephyr/dts/arm/st/f4/stm32f405.dtsi:101 */
			interrupt-names = "global";     /* in zephyr/dts/arm/st/f4/stm32f405.dtsi:102 */
			st,prescaler = < 0x0 >;         /* in zephyr/dts/arm/st/f4/stm32f405.dtsi:103 */
			status = "disabled";            /* in zephyr/dts/arm/st/f4/stm32f405.dtsi:104 */

			/* node '/soc/timers@40001400/counter' defined in zephyr/dts/arm/st/f4/stm32f405.dtsi:106 */
			counter {
				compatible = "st,stm32-counter"; /* in zephyr/dts/arm/st/f4/stm32f405.dtsi:107 */
				status = "disabled";             /* in zephyr/dts/arm/st/f4/stm32f405.dtsi:108 */
			};
		};

		/* node '/soc/timers@40010400' defined in zephyr/dts/arm/st/f4/stm32f405.dtsi:112 */
		timers8: timers@40010400 {
			compatible = "st,stm32-timers"; /* in zephyr/dts/arm/st/f4/stm32f405.dtsi:113 */
			reg = < 0x40010400 0x400 >;     /* in zephyr/dts/arm/st/f4/stm32f405.dtsi:114 */
			clocks = < &rcc 0x44 0x2 >,
			         < &rcc 0xd 0xff >;     /* in zephyr/dts/arm/st/f4/stm32f405.dtsi:115 */
			resets = < &rctl 0x481 >;       /* in zephyr/dts/arm/st/f4/stm32f405.dtsi:117 */
			interrupts = < 0x2b 0x0 >,
			             < 0x2c 0x0 >,
			             < 0x2d 0x0 >,
			             < 0x2e 0x0 >;      /* in zephyr/dts/arm/st/f4/stm32f405.dtsi:118 */
			interrupt-names = "brk",
			                  "up",
			                  "trgcom",
			                  "cc";         /* in zephyr/dts/arm/st/f4/stm32f405.dtsi:119 */
			st,prescaler = < 0x0 >;         /* in zephyr/dts/arm/st/f4/stm32f405.dtsi:120 */
			status = "disabled";            /* in zephyr/dts/arm/st/f4/stm32f405.dtsi:121 */

			/* node '/soc/timers@40010400/pwm' defined in zephyr/dts/arm/st/f4/stm32f405.dtsi:123 */
			pwm {
				compatible = "st,stm32-pwm"; /* in zephyr/dts/arm/st/f4/stm32f405.dtsi:124 */
				status = "disabled";         /* in zephyr/dts/arm/st/f4/stm32f405.dtsi:125 */
				#pwm-cells = < 0x3 >;        /* in zephyr/dts/arm/st/f4/stm32f405.dtsi:126 */
			};

			/* node '/soc/timers@40010400/qdec' defined in zephyr/dts/arm/st/f4/stm32f405.dtsi:129 */
			qdec {
				compatible = "st,stm32-qdec";    /* in zephyr/dts/arm/st/f4/stm32f405.dtsi:130 */
				st,input-filter-level = < 0x0 >; /* in zephyr/dts/arm/st/f4/stm32f405.dtsi:131 */
				status = "disabled";             /* in zephyr/dts/arm/st/f4/stm32f405.dtsi:132 */
			};
		};

		/* node '/soc/timers@40001800' defined in zephyr/dts/arm/st/f4/stm32f405.dtsi:136 */
		timers12: timers@40001800 {
			compatible = "st,stm32-timers"; /* in zephyr/dts/arm/st/f4/stm32f405.dtsi:137 */
			reg = < 0x40001800 0x400 >;     /* in zephyr/dts/arm/st/f4/stm32f405.dtsi:138 */
			clocks = < &rcc 0x40 0x40 >,
			         < &rcc 0xc 0xff >;     /* in zephyr/dts/arm/st/f4/stm32f405.dtsi:139 */
			resets = < &rctl 0x406 >;       /* in zephyr/dts/arm/st/f4/stm32f405.dtsi:141 */
			interrupts = < 0x2b 0x0 >;      /* in zephyr/dts/arm/st/f4/stm32f405.dtsi:142 */
			interrupt-names = "global";     /* in zephyr/dts/arm/st/f4/stm32f405.dtsi:143 */
			st,prescaler = < 0x0 >;         /* in zephyr/dts/arm/st/f4/stm32f405.dtsi:144 */
			status = "disabled";            /* in zephyr/dts/arm/st/f4/stm32f405.dtsi:145 */

			/* node '/soc/timers@40001800/pwm' defined in zephyr/dts/arm/st/f4/stm32f405.dtsi:147 */
			pwm {
				compatible = "st,stm32-pwm"; /* in zephyr/dts/arm/st/f4/stm32f405.dtsi:148 */
				status = "disabled";         /* in zephyr/dts/arm/st/f4/stm32f405.dtsi:149 */
				#pwm-cells = < 0x3 >;        /* in zephyr/dts/arm/st/f4/stm32f405.dtsi:150 */
			};

			/* node '/soc/timers@40001800/counter' defined in zephyr/dts/arm/st/f4/stm32f405.dtsi:153 */
			counter {
				compatible = "st,stm32-counter"; /* in zephyr/dts/arm/st/f4/stm32f405.dtsi:154 */
				status = "disabled";             /* in zephyr/dts/arm/st/f4/stm32f405.dtsi:155 */
			};
		};

		/* node '/soc/timers@40001c00' defined in zephyr/dts/arm/st/f4/stm32f405.dtsi:159 */
		timers13: timers@40001c00 {
			compatible = "st,stm32-timers"; /* in zephyr/dts/arm/st/f4/stm32f405.dtsi:160 */
			reg = < 0x40001c00 0x400 >;     /* in zephyr/dts/arm/st/f4/stm32f405.dtsi:161 */
			clocks = < &rcc 0x40 0x80 >,
			         < &rcc 0xc 0xff >;     /* in zephyr/dts/arm/st/f4/stm32f405.dtsi:162 */
			resets = < &rctl 0x407 >;       /* in zephyr/dts/arm/st/f4/stm32f405.dtsi:164 */
			interrupts = < 0x2c 0x0 >;      /* in zephyr/dts/arm/st/f4/stm32f405.dtsi:165 */
			interrupt-names = "global";     /* in zephyr/dts/arm/st/f4/stm32f405.dtsi:166 */
			st,prescaler = < 0x0 >;         /* in zephyr/dts/arm/st/f4/stm32f405.dtsi:167 */
			status = "disabled";            /* in zephyr/dts/arm/st/f4/stm32f405.dtsi:168 */

			/* node '/soc/timers@40001c00/pwm' defined in zephyr/dts/arm/st/f4/stm32f405.dtsi:170 */
			pwm {
				compatible = "st,stm32-pwm"; /* in zephyr/dts/arm/st/f4/stm32f405.dtsi:171 */
				status = "disabled";         /* in zephyr/dts/arm/st/f4/stm32f405.dtsi:172 */
				#pwm-cells = < 0x3 >;        /* in zephyr/dts/arm/st/f4/stm32f405.dtsi:173 */
			};

			/* node '/soc/timers@40001c00/counter' defined in zephyr/dts/arm/st/f4/stm32f405.dtsi:176 */
			counter {
				compatible = "st,stm32-counter"; /* in zephyr/dts/arm/st/f4/stm32f405.dtsi:177 */
				status = "disabled";             /* in zephyr/dts/arm/st/f4/stm32f405.dtsi:178 */
			};
		};

		/* node '/soc/timers@40002000' defined in zephyr/dts/arm/st/f4/stm32f405.dtsi:182 */
		timers14: timers@40002000 {
			compatible = "st,stm32-timers"; /* in zephyr/dts/arm/st/f4/stm32f405.dtsi:183 */
			reg = < 0x40002000 0x400 >;     /* in zephyr/dts/arm/st/f4/stm32f405.dtsi:184 */
			clocks = < &rcc 0x40 0x100 >,
			         < &rcc 0xc 0xff >;     /* in zephyr/dts/arm/st/f4/stm32f405.dtsi:185 */
			resets = < &rctl 0x408 >;       /* in zephyr/dts/arm/st/f4/stm32f405.dtsi:187 */
			interrupts = < 0x2d 0x0 >;      /* in zephyr/dts/arm/st/f4/stm32f405.dtsi:188 */
			interrupt-names = "global";     /* in zephyr/dts/arm/st/f4/stm32f405.dtsi:189 */
			st,prescaler = < 0x0 >;         /* in zephyr/dts/arm/st/f4/stm32f405.dtsi:190 */
			status = "disabled";            /* in zephyr/dts/arm/st/f4/stm32f405.dtsi:191 */

			/* node '/soc/timers@40002000/pwm' defined in zephyr/dts/arm/st/f4/stm32f405.dtsi:193 */
			pwm {
				compatible = "st,stm32-pwm"; /* in zephyr/dts/arm/st/f4/stm32f405.dtsi:194 */
				status = "disabled";         /* in zephyr/dts/arm/st/f4/stm32f405.dtsi:195 */
				#pwm-cells = < 0x3 >;        /* in zephyr/dts/arm/st/f4/stm32f405.dtsi:196 */
			};

			/* node '/soc/timers@40002000/counter' defined in zephyr/dts/arm/st/f4/stm32f405.dtsi:199 */
			counter {
				compatible = "st,stm32-counter"; /* in zephyr/dts/arm/st/f4/stm32f405.dtsi:200 */
				status = "disabled";             /* in zephyr/dts/arm/st/f4/stm32f405.dtsi:201 */
			};
		};

		/* node '/soc/usb@40040000' defined in zephyr/dts/arm/st/f4/stm32f405.dtsi:205 */
		usbotg_hs: usb@40040000 {
			compatible = "st,stm32-otghs";     /* in zephyr/dts/arm/st/f4/stm32f405.dtsi:206 */
			reg = < 0x40040000 0x40000 >;      /* in zephyr/dts/arm/st/f4/stm32f405.dtsi:207 */
			interrupts = < 0x4d 0x0 >,
			             < 0x4a 0x0 >,
			             < 0x4b 0x0 >;         /* in zephyr/dts/arm/st/f4/stm32f405.dtsi:208 */
			interrupt-names = "otghs",
			                  "ep1_out",
			                  "ep1_in";        /* in zephyr/dts/arm/st/f4/stm32f405.dtsi:209 */
			num-bidir-endpoints = < 0x6 >;     /* in zephyr/dts/arm/st/f4/stm32f405.dtsi:210 */
			ram-size = < 0x1000 >;             /* in zephyr/dts/arm/st/f4/stm32f405.dtsi:211 */
			maximum-speed = "full-speed";      /* in zephyr/dts/arm/st/f4/stm32f405.dtsi:212 */
			phys = < &otghs_fs_phy >;          /* in zephyr/dts/arm/st/f4/stm32f405.dtsi:213 */
			clocks = < &rcc 0x30 0x20000000 >,
			         < &rcc 0x7 0xff >;        /* in zephyr/dts/arm/st/f4/stm32f405.dtsi:214 */
			status = "disabled";               /* in zephyr/dts/arm/st/f4/stm32f405.dtsi:216 */
		};

		/* node '/soc/can@40006400' defined in zephyr/dts/arm/st/f4/stm32f405.dtsi:219 */
		can1: can@40006400 {
			compatible = "st,stm32-bxcan";    /* in zephyr/dts/arm/st/f4/stm32f405.dtsi:220 */
			reg = < 0x40006400 0x400 >;       /* in zephyr/dts/arm/st/f4/stm32f405.dtsi:221 */
			interrupts = < 0x13 0x0 >,
			             < 0x14 0x0 >,
			             < 0x15 0x0 >,
			             < 0x16 0x0 >;        /* in zephyr/dts/arm/st/f4/stm32f405.dtsi:222 */
			interrupt-names = "TX",
			                  "RX0",
			                  "RX1",
			                  "SCE";          /* in zephyr/dts/arm/st/f4/stm32f405.dtsi:223 */
			clocks = < &rcc 0x40 0x2000000 >; /* in zephyr/dts/arm/st/f4/stm32f405.dtsi:224 */
			status = "disabled";              /* in zephyr/dts/arm/st/f4/stm32f405.dtsi:225 */
		};

		/* node '/soc/can@40006800' defined in zephyr/dts/arm/st/f4/stm32f405.dtsi:228 */
		can2: can@40006800 {
			compatible = "st,stm32-bxcan";    /* in zephyr/dts/arm/st/f4/stm32f405.dtsi:229 */
			reg = < 0x40006800 0x400 >;       /* in zephyr/dts/arm/st/f4/stm32f405.dtsi:230 */
			interrupts = < 0x3f 0x0 >,
			             < 0x40 0x0 >,
			             < 0x41 0x0 >,
			             < 0x42 0x0 >;        /* in zephyr/dts/arm/st/f4/stm32f405.dtsi:231 */
			interrupt-names = "TX",
			                  "RX0",
			                  "RX1",
			                  "SCE";          /* in zephyr/dts/arm/st/f4/stm32f405.dtsi:232 */
			clocks = < &rcc 0x40 0x6000000 >; /* in zephyr/dts/arm/st/f4/stm32f405.dtsi:234 */
			master-can-reg = < 0x40006400 >;  /* in zephyr/dts/arm/st/f4/stm32f405.dtsi:235 */
			status = "disabled";              /* in zephyr/dts/arm/st/f4/stm32f405.dtsi:236 */
		};

		/* node '/soc/rng@50060800' defined in zephyr/dts/arm/st/f4/stm32f405.dtsi:239 */
		rng: rng@50060800 {
			compatible = "st,stm32-rng"; /* in zephyr/dts/arm/st/f4/stm32f405.dtsi:240 */
			reg = < 0x50060800 0x400 >;  /* in zephyr/dts/arm/st/f4/stm32f405.dtsi:241 */
			interrupts = < 0x50 0x0 >;   /* in zephyr/dts/arm/st/f4/stm32f405.dtsi:242 */
			clocks = < &rcc 0x34 0x40 >; /* in zephyr/dts/arm/st/f4/stm32f405.dtsi:243 */
			status = "okay";             /* in zephyr/boards/st/nucleo_f429zi/nucleo_f429zi.dts:175 */
		};

		/* node '/soc/memory@40024000' defined in zephyr/dts/arm/st/f4/stm32f405.dtsi:247 */
		backup_sram: memory@40024000 {
			compatible = "zephyr,memory-region",
			             "st,stm32-backup-sram";  /* in zephyr/dts/arm/st/f4/stm32f405.dtsi:248 */
			reg = < 0x40024000 0x1000 >;          /* in zephyr/dts/arm/st/f4/stm32f405.dtsi:249 */
			clocks = < &rcc 0x30 0x40000 >;       /* in zephyr/dts/arm/st/f4/stm32f405.dtsi:250 */
			zephyr,memory-region = "BACKUP_SRAM"; /* in zephyr/dts/arm/st/f4/stm32f405.dtsi:251 */
			status = "disabled";                  /* in zephyr/dts/arm/st/f4/stm32f405.dtsi:252 */
		};

		/* node '/soc/adc@40012100' defined in zephyr/dts/arm/st/f4/stm32f405.dtsi:255 */
		adc2: adc@40012100 {
			compatible = "st,stm32-adc";                                 /* in zephyr/dts/arm/st/f4/stm32f405.dtsi:256 */
			reg = < 0x40012100 0x50 >;                                   /* in zephyr/dts/arm/st/f4/stm32f405.dtsi:257 */
			clocks = < &rcc 0x44 0x200 >;                                /* in zephyr/dts/arm/st/f4/stm32f405.dtsi:258 */
			clock-names = "adcx";                                        /* in zephyr/dts/arm/st/f4/stm32f405.dtsi:259 */
			interrupts = < 0x12 0x0 >;                                   /* in zephyr/dts/arm/st/f4/stm32f405.dtsi:260 */
			#io-channel-cells = < 0x1 >;                                 /* in zephyr/dts/arm/st/f4/stm32f405.dtsi:261 */
			resolutions = < 0x607804 0x517804 0x427804 0x337804 >;       /* in zephyr/dts/arm/st/f4/stm32f405.dtsi:262 */
			sampling-times = < 0x3 0xf 0x1c 0x38 0x54 0x70 0x90 0x1e0 >; /* in zephyr/dts/arm/st/f4/stm32f405.dtsi:266 */
			st,adc-clock-source = "SYNC";                                /* in zephyr/dts/arm/st/f4/stm32f405.dtsi:267 */
			st,adc-sequencer = "programmable";                           /* in zephyr/dts/arm/st/f4/stm32f405.dtsi:268 */
			st,adc-oversampler = "none";                                 /* in zephyr/dts/arm/st/f4/stm32f405.dtsi:269 */
			st,adc-internal-regulator = "none";                          /* in zephyr/dts/arm/st/f4/stm32f405.dtsi:270 */
			status = "disabled";                                         /* in zephyr/dts/arm/st/f4/stm32f405.dtsi:271 */
		};

		/* node '/soc/adc@40012200' defined in zephyr/dts/arm/st/f4/stm32f405.dtsi:274 */
		adc3: adc@40012200 {
			compatible = "st,stm32-adc";                                 /* in zephyr/dts/arm/st/f4/stm32f405.dtsi:275 */
			reg = < 0x40012200 0x50 >;                                   /* in zephyr/dts/arm/st/f4/stm32f405.dtsi:276 */
			clocks = < &rcc 0x44 0x400 >;                                /* in zephyr/dts/arm/st/f4/stm32f405.dtsi:277 */
			clock-names = "adcx";                                        /* in zephyr/dts/arm/st/f4/stm32f405.dtsi:278 */
			interrupts = < 0x12 0x0 >;                                   /* in zephyr/dts/arm/st/f4/stm32f405.dtsi:279 */
			#io-channel-cells = < 0x1 >;                                 /* in zephyr/dts/arm/st/f4/stm32f405.dtsi:280 */
			resolutions = < 0x607804 0x517804 0x427804 0x337804 >;       /* in zephyr/dts/arm/st/f4/stm32f405.dtsi:281 */
			sampling-times = < 0x3 0xf 0x1c 0x38 0x54 0x70 0x90 0x1e0 >; /* in zephyr/dts/arm/st/f4/stm32f405.dtsi:285 */
			st,adc-clock-source = "SYNC";                                /* in zephyr/dts/arm/st/f4/stm32f405.dtsi:286 */
			st,adc-sequencer = "programmable";                           /* in zephyr/dts/arm/st/f4/stm32f405.dtsi:287 */
			st,adc-oversampler = "none";                                 /* in zephyr/dts/arm/st/f4/stm32f405.dtsi:288 */
			st,adc-internal-regulator = "none";                          /* in zephyr/dts/arm/st/f4/stm32f405.dtsi:289 */
			status = "disabled";                                         /* in zephyr/dts/arm/st/f4/stm32f405.dtsi:290 */
		};

		/* node '/soc/dac@40007400' defined in zephyr/dts/arm/st/f4/stm32f405.dtsi:293 */
		dac1: dac@40007400 {
			compatible = "st,stm32-dac";       /* in zephyr/dts/arm/st/f4/stm32f429.dtsi:15 */
			reg = < 0x40007400 0x400 >;        /* in zephyr/dts/arm/st/f4/stm32f429.dtsi:16 */
			clocks = < &rcc 0x40 0x20000000 >; /* in zephyr/dts/arm/st/f4/stm32f429.dtsi:17 */
			#io-channel-cells = < 0x1 >;       /* in zephyr/dts/arm/st/f4/stm32f429.dtsi:19 */
			status = "okay";                   /* in zephyr/boards/st/nucleo_f429zi/nucleo_f429zi.dts:107 */
			pinctrl-0 = < &dac_out1_pa4 >;     /* in zephyr/boards/st/nucleo_f429zi/nucleo_f429zi.dts:108 */
			pinctrl-names = "default";         /* in zephyr/boards/st/nucleo_f429zi/nucleo_f429zi.dts:109 */
		};

		/* node '/soc/ethernet@40028000' defined in zephyr/dts/arm/st/f4/stm32f407.dtsi:13 */
		ethernet@40028000 {
			reg = < 0x40028000 0x8000 >;                 /* in zephyr/dts/arm/st/f4/stm32f407.dtsi:14 */
			compatible = "st,stm32-ethernet-controller"; /* in zephyr/dts/arm/st/f4/stm32f407.dtsi:15 */
			clock-names = "stm-eth";                     /* in zephyr/dts/arm/st/f4/stm32f407.dtsi:16 */
			clocks = < &rcc 0x30 0x2000000 >;            /* in zephyr/dts/arm/st/f4/stm32f407.dtsi:17 */

			/* node '/soc/ethernet@40028000/ethernet' defined in zephyr/dts/arm/st/f4/stm32f407.dtsi:19 */
			mac: ethernet {
				compatible = "st,stm32-ethernet";                                                                         /* in zephyr/dts/arm/st/f4/stm32f407.dtsi:20 */
				interrupts = < 0x3d 0x0 >;                                                                                /* in zephyr/dts/arm/st/f4/stm32f407.dtsi:21 */
				clock-names = "mac-clk-tx",
				              "mac-clk-rx",
				              "mac-clk-ptp";                                                                              /* in zephyr/dts/arm/st/f4/stm32f407.dtsi:22 */
				clocks = < &rcc 0x30 0x4000000 >,
				         < &rcc 0x30 0x8000000 >,
				         < &rcc 0x30 0x10000000 >;                                                                        /* in zephyr/dts/arm/st/f4/stm32f407.dtsi:24 */
				status = "okay";                                                                                          /* in zephyr/boards/st/nucleo_f429zi/nucleo_f429zi.dts:183 */
				pinctrl-0 = < &eth_rxd0_pc4 &eth_rxd1_pc5 &eth_ref_clk_pa1 &eth_crs_dv_pa7 &eth_tx_en_pg11 &eth_txd0_pg13
				              &eth_txd1_pb13 >;                                                                           /* in zephyr/boards/st/nucleo_f429zi/nucleo_f429zi.dts:184 */
				pinctrl-names = "default";                                                                                /* in zephyr/boards/st/nucleo_f429zi/nucleo_f429zi.dts:191 */
				phy-connection-type = "rmii";                                                                             /* in zephyr/boards/st/nucleo_f429zi/nucleo_f429zi.dts:192 */
				phy-handle = < &eth_phy >;                                                                                /* in zephyr/boards/st/nucleo_f429zi/nucleo_f429zi.dts:193 */
			};

			/* node '/soc/ethernet@40028000/mdio' defined in zephyr/dts/arm/st/f4/stm32f407.dtsi:30 */
			mdio: mdio {
				compatible = "st,stm32-mdio";               /* in zephyr/dts/arm/st/f4/stm32f407.dtsi:31 */
				#address-cells = < 0x1 >;                   /* in zephyr/dts/arm/st/f4/stm32f407.dtsi:32 */
				#size-cells = < 0x0 >;                      /* in zephyr/dts/arm/st/f4/stm32f407.dtsi:33 */
				status = "okay";                            /* in zephyr/boards/st/nucleo_f429zi/nucleo_f429zi.dts:197 */
				pinctrl-0 = < &eth_mdio_pa2 &eth_mdc_pc1 >; /* in zephyr/boards/st/nucleo_f429zi/nucleo_f429zi.dts:198 */
				pinctrl-names = "default";                  /* in zephyr/boards/st/nucleo_f429zi/nucleo_f429zi.dts:199 */

				/* node '/soc/ethernet@40028000/mdio/ethernet-phy@0' defined in zephyr/boards/st/nucleo_f429zi/nucleo_f429zi.dts:201 */
				eth_phy: ethernet-phy@0 {
					compatible = "ethernet-phy"; /* in zephyr/boards/st/nucleo_f429zi/nucleo_f429zi.dts:202 */
					reg = < 0x0 >;               /* in zephyr/boards/st/nucleo_f429zi/nucleo_f429zi.dts:203 */
					phandle = < 0x20 >;          /* in zephyr/boards/st/nucleo_f429zi/nucleo_f429zi.dts:193 */
				};
			};
		};

		/* node '/soc/serial@40007800' defined in zephyr/dts/arm/st/f4/stm32f427.dtsi:48 */
		uart7: serial@40007800 {
			compatible = "st,stm32-uart";      /* in zephyr/dts/arm/st/f4/stm32f427.dtsi:49 */
			reg = < 0x40007800 0x400 >;        /* in zephyr/dts/arm/st/f4/stm32f427.dtsi:50 */
			clocks = < &rcc 0x40 0x40000000 >; /* in zephyr/dts/arm/st/f4/stm32f427.dtsi:51 */
			resets = < &rctl 0x41e >;          /* in zephyr/dts/arm/st/f4/stm32f427.dtsi:52 */
			interrupts = < 0x52 0x0 >;         /* in zephyr/dts/arm/st/f4/stm32f427.dtsi:53 */
			status = "disabled";               /* in zephyr/dts/arm/st/f4/stm32f427.dtsi:54 */
		};

		/* node '/soc/serial@40007c00' defined in zephyr/dts/arm/st/f4/stm32f427.dtsi:57 */
		uart8: serial@40007c00 {
			compatible = "st,stm32-uart";      /* in zephyr/dts/arm/st/f4/stm32f427.dtsi:58 */
			reg = < 0x40007c00 0x400 >;        /* in zephyr/dts/arm/st/f4/stm32f427.dtsi:59 */
			clocks = < &rcc 0x40 0x80000000 >; /* in zephyr/dts/arm/st/f4/stm32f427.dtsi:60 */
			resets = < &rctl 0x41f >;          /* in zephyr/dts/arm/st/f4/stm32f427.dtsi:61 */
			interrupts = < 0x53 0x0 >;         /* in zephyr/dts/arm/st/f4/stm32f427.dtsi:62 */
			status = "disabled";               /* in zephyr/dts/arm/st/f4/stm32f427.dtsi:63 */
		};

		/* node '/soc/spi@40015000' defined in zephyr/dts/arm/st/f4/stm32f427.dtsi:79 */
		spi5: spi@40015000 {
			compatible = "st,stm32-spi";     /* in zephyr/dts/arm/st/f4/stm32f427.dtsi:80 */
			#address-cells = < 0x1 >;        /* in zephyr/dts/arm/st/f4/stm32f427.dtsi:81 */
			#size-cells = < 0x0 >;           /* in zephyr/dts/arm/st/f4/stm32f427.dtsi:82 */
			reg = < 0x40015000 0x400 >;      /* in zephyr/dts/arm/st/f4/stm32f427.dtsi:83 */
			clocks = < &rcc 0x44 0x100000 >; /* in zephyr/dts/arm/st/f4/stm32f427.dtsi:84 */
			interrupts = < 0x55 0x5 >;       /* in zephyr/dts/arm/st/f4/stm32f427.dtsi:85 */
			status = "disabled";             /* in zephyr/dts/arm/st/f4/stm32f427.dtsi:86 */
		};

		/* node '/soc/spi@40015400' defined in zephyr/dts/arm/st/f4/stm32f427.dtsi:92 */
		spi6: spi@40015400 {
			compatible = "st,stm32-spi";     /* in zephyr/dts/arm/st/f4/stm32f427.dtsi:93 */
			#address-cells = < 0x1 >;        /* in zephyr/dts/arm/st/f4/stm32f427.dtsi:94 */
			#size-cells = < 0x0 >;           /* in zephyr/dts/arm/st/f4/stm32f427.dtsi:95 */
			reg = < 0x40015400 0x400 >;      /* in zephyr/dts/arm/st/f4/stm32f427.dtsi:96 */
			clocks = < &rcc 0x44 0x200000 >; /* in zephyr/dts/arm/st/f4/stm32f427.dtsi:97 */
			interrupts = < 0x56 0x5 >;       /* in zephyr/dts/arm/st/f4/stm32f427.dtsi:98 */
			status = "disabled";             /* in zephyr/dts/arm/st/f4/stm32f427.dtsi:99 */
		};

		/* node '/soc/memory-controller@a0000000' defined in zephyr/dts/arm/st/f4/stm32f427.dtsi:102 */
		fmc: memory-controller@a0000000 {
			compatible = "st,stm32-fmc"; /* in zephyr/dts/arm/st/f4/stm32f427.dtsi:103 */
			reg = < 0xa0000000 0x400 >;  /* in zephyr/dts/arm/st/f4/stm32f427.dtsi:104 */
			clocks = < &rcc 0x38 0x1 >;  /* in zephyr/dts/arm/st/f4/stm32f427.dtsi:105 */
			status = "disabled";         /* in zephyr/dts/arm/st/f4/stm32f427.dtsi:106 */

			/* node '/soc/memory-controller@a0000000/sdram' defined in zephyr/dts/arm/st/f4/stm32f427.dtsi:108 */
			sdram: sdram {
				compatible = "st,stm32-fmc-sdram"; /* in zephyr/dts/arm/st/f4/stm32f427.dtsi:109 */
				#address-cells = < 0x1 >;          /* in zephyr/dts/arm/st/f4/stm32f427.dtsi:110 */
				#size-cells = < 0x0 >;             /* in zephyr/dts/arm/st/f4/stm32f427.dtsi:111 */
				status = "disabled";               /* in zephyr/dts/arm/st/f4/stm32f427.dtsi:112 */
			};
		};

		/* node '/soc/sai1@40015804' defined in zephyr/dts/arm/st/f4/stm32f427.dtsi:116 */
		sai1_a: sai1@40015804 {
			compatible = "st,stm32-sai";          /* in zephyr/dts/arm/st/f4/stm32f427.dtsi:117 */
			#address-cells = < 0x1 >;             /* in zephyr/dts/arm/st/f4/stm32f427.dtsi:118 */
			#size-cells = < 0x0 >;                /* in zephyr/dts/arm/st/f4/stm32f427.dtsi:119 */
			reg = < 0x40015804 0x20 >;            /* in zephyr/dts/arm/st/f4/stm32f427.dtsi:120 */
			clocks = < &rcc 0x44 0x400000 >;      /* in zephyr/dts/arm/st/f4/stm32f427.dtsi:121 */
			dmas = < &dma2 0x1 0x0 0x22800 0x0 >; /* in zephyr/dts/arm/st/f4/stm32f427.dtsi:122 */
			status = "disabled";                  /* in zephyr/dts/arm/st/f4/stm32f427.dtsi:124 */
		};

		/* node '/soc/sai1@40015824' defined in zephyr/dts/arm/st/f4/stm32f427.dtsi:127 */
		sai1_b: sai1@40015824 {
			compatible = "st,stm32-sai";          /* in zephyr/dts/arm/st/f4/stm32f427.dtsi:128 */
			#address-cells = < 0x1 >;             /* in zephyr/dts/arm/st/f4/stm32f427.dtsi:129 */
			#size-cells = < 0x0 >;                /* in zephyr/dts/arm/st/f4/stm32f427.dtsi:130 */
			reg = < 0x40015824 0x20 >;            /* in zephyr/dts/arm/st/f4/stm32f427.dtsi:131 */
			clocks = < &rcc 0x44 0x400000 >;      /* in zephyr/dts/arm/st/f4/stm32f427.dtsi:132 */
			dmas = < &dma2 0x5 0x0 0x22800 0x0 >; /* in zephyr/dts/arm/st/f4/stm32f427.dtsi:133 */
			status = "disabled";                  /* in zephyr/dts/arm/st/f4/stm32f427.dtsi:135 */
		};

		/* node '/soc/display-controller@40016800' defined in zephyr/dts/arm/st/f4/stm32f429.dtsi:22 */
		ltdc: display-controller@40016800 {
			compatible = "st,stm32-ltdc";     /* in zephyr/dts/arm/st/f4/stm32f429.dtsi:23 */
			reg = < 0x40016800 0x200 >;       /* in zephyr/dts/arm/st/f4/stm32f429.dtsi:24 */
			interrupts = < 0x58 0x0 >,
			             < 0x59 0x0 >;        /* in zephyr/dts/arm/st/f4/stm32f429.dtsi:25 */
			interrupt-names = "ltdc",
			                  "ltdc_er";      /* in zephyr/dts/arm/st/f4/stm32f429.dtsi:26 */
			clocks = < &rcc 0x44 0x4000000 >; /* in zephyr/dts/arm/st/f4/stm32f429.dtsi:27 */
			resets = < &rctl 0x49a >;         /* in zephyr/dts/arm/st/f4/stm32f429.dtsi:28 */
			status = "disabled";              /* in zephyr/dts/arm/st/f4/stm32f429.dtsi:29 */
		};
	};

	/* node '/cpus' defined in zephyr/dts/arm/st/f4/stm32f4.dtsi:31 */
	cpus {
		#address-cells = < 0x1 >; /* in zephyr/dts/arm/st/f4/stm32f4.dtsi:32 */
		#size-cells = < 0x0 >;    /* in zephyr/dts/arm/st/f4/stm32f4.dtsi:33 */

		/* node '/cpus/cpu@0' defined in zephyr/dts/arm/st/f4/stm32f4.dtsi:35 */
		cpu0: cpu@0 {
			device_type = "cpu";           /* in zephyr/dts/arm/st/f4/stm32f4.dtsi:36 */
			compatible = "arm,cortex-m4f"; /* in zephyr/dts/arm/st/f4/stm32f4.dtsi:37 */
			reg = < 0x0 >;                 /* in zephyr/dts/arm/st/f4/stm32f4.dtsi:38 */
			cpu-power-states = < &stop >;  /* in zephyr/dts/arm/st/f4/stm32f4.dtsi:39 */
		};

		/* node '/cpus/power-states' defined in zephyr/dts/arm/st/f4/stm32f4.dtsi:42 */
		power-states {

			/* node '/cpus/power-states/stop' defined in zephyr/dts/arm/st/f4/stm32f4.dtsi:43 */
			stop: stop {
				compatible = "zephyr,power-state";    /* in zephyr/dts/arm/st/f4/stm32f4.dtsi:44 */
				power-state-name = "suspend-to-idle"; /* in zephyr/dts/arm/st/f4/stm32f4.dtsi:45 */
				min-residency-us = < 0x190 >;         /* in zephyr/dts/arm/st/f4/stm32f4.dtsi:52 */
				exit-latency-us = < 0x12c >;          /* in zephyr/dts/arm/st/f4/stm32f4.dtsi:53 */
				phandle = < 0x24 >;                   /* in zephyr/dts/arm/st/f4/stm32f4.dtsi:39 */
			};
		};
	};

	/* node '/memory@20000000' defined in zephyr/dts/arm/st/f4/stm32f4.dtsi:58 */
	sram0: memory@20000000 {
		compatible = "zephyr,memory-region",
		             "mmio-sram";            /* in zephyr/dts/arm/st/f4/stm32f4.dtsi:59 */
		zephyr,memory-region = "SRAM0";      /* in zephyr/dts/arm/st/f4/stm32f4.dtsi:60 */
		reg = < 0x20000000 0x30000 >;        /* in zephyr/dts/arm/st/f4/stm32f429Xi.dtsi:17 */
	};

	/* node '/clocks' defined in zephyr/dts/arm/st/f4/stm32f4.dtsi:63 */
	clocks {

		/* node '/clocks/clk-hse' defined in zephyr/dts/arm/st/f4/stm32f4.dtsi:64 */
		clk_hse: clk-hse {
			#clock-cells = < 0x0 >;            /* in zephyr/dts/arm/st/f4/stm32f4.dtsi:65 */
			compatible = "st,stm32-hse-clock"; /* in zephyr/dts/arm/st/f4/stm32f4.dtsi:66 */
			hse-bypass;                        /* in zephyr/boards/st/nucleo_f429zi/nucleo_f429zi.dts:72 */
			clock-frequency = < 0x7a1200 >;    /* in zephyr/boards/st/nucleo_f429zi/nucleo_f429zi.dts:73 */
			status = "okay";                   /* in zephyr/boards/st/nucleo_f429zi/nucleo_f429zi.dts:74 */
			phandle = < 0x25 >;                /* in zephyr/boards/st/nucleo_f429zi/nucleo_f429zi.dts:82 */
		};

		/* node '/clocks/clk-hsi' defined in zephyr/dts/arm/st/f4/stm32f4.dtsi:70 */
		clk_hsi: clk-hsi {
			#clock-cells = < 0x0 >;         /* in zephyr/dts/arm/st/f4/stm32f4.dtsi:71 */
			compatible = "fixed-clock";     /* in zephyr/dts/arm/st/f4/stm32f4.dtsi:72 */
			clock-frequency = < 0xf42400 >; /* in zephyr/dts/arm/st/f4/stm32f4.dtsi:73 */
			status = "disabled";            /* in zephyr/dts/arm/st/f4/stm32f4.dtsi:74 */
		};

		/* node '/clocks/clk-lse' defined in zephyr/dts/arm/st/f4/stm32f4.dtsi:77 */
		clk_lse: clk-lse {
			#clock-cells = < 0x0 >;       /* in zephyr/dts/arm/st/f4/stm32f4.dtsi:78 */
			compatible = "fixed-clock";   /* in zephyr/dts/arm/st/f4/stm32f4.dtsi:79 */
			clock-frequency = < 0x8000 >; /* in zephyr/dts/arm/st/f4/stm32f4.dtsi:80 */
			status = "disabled";          /* in zephyr/dts/arm/st/f4/stm32f4.dtsi:81 */
		};

		/* node '/clocks/clk-lsi' defined in zephyr/dts/arm/st/f4/stm32f4.dtsi:84 */
		clk_lsi: clk-lsi {
			#clock-cells = < 0x0 >;       /* in zephyr/dts/arm/st/f4/stm32f4.dtsi:85 */
			compatible = "fixed-clock";   /* in zephyr/dts/arm/st/f4/stm32f4.dtsi:86 */
			clock-frequency = < 0x7d00 >; /* in zephyr/dts/arm/st/f4/stm32f4.dtsi:87 */
			status = "okay";              /* in zephyr/boards/st/nucleo_f429zi/nucleo_f429zi.dts:68 */
		};

		/* node '/clocks/pll' defined in zephyr/dts/arm/st/f4/stm32f4.dtsi:91 */
		pll: pll {
			#clock-cells = < 0x0 >;              /* in zephyr/dts/arm/st/f4/stm32f4.dtsi:92 */
			compatible = "st,stm32f4-pll-clock"; /* in zephyr/dts/arm/st/f4/stm32f4.dtsi:93 */
			div-m = < 0x8 >;                     /* in zephyr/boards/st/nucleo_f429zi/nucleo_f429zi.dts:78 */
			mul-n = < 0x150 >;                   /* in zephyr/boards/st/nucleo_f429zi/nucleo_f429zi.dts:79 */
			div-p = < 0x2 >;                     /* in zephyr/boards/st/nucleo_f429zi/nucleo_f429zi.dts:80 */
			div-q = < 0x7 >;                     /* in zephyr/boards/st/nucleo_f429zi/nucleo_f429zi.dts:81 */
			clocks = < &clk_hse >;               /* in zephyr/boards/st/nucleo_f429zi/nucleo_f429zi.dts:82 */
			status = "okay";                     /* in zephyr/boards/st/nucleo_f429zi/nucleo_f429zi.dts:83 */
			phandle = < 0x2 >;                   /* in zephyr/boards/st/nucleo_f429zi/nucleo_f429zi.dts:87 */
		};

		/* node '/clocks/plli2s' defined in zephyr/dts/arm/st/f4/stm32f401.dtsi:11 */
		plli2s: plli2s {
			#clock-cells = < 0x0 >;                 /* in zephyr/dts/arm/st/f4/stm32f401.dtsi:12 */
			compatible = "st,stm32f4-plli2s-clock"; /* in zephyr/dts/arm/st/f4/stm32f401.dtsi:13 */
			status = "disabled";                    /* in zephyr/dts/arm/st/f4/stm32f401.dtsi:14 */
		};

		/* node '/clocks/pllsai' defined in zephyr/dts/arm/st/f4/stm32f427.dtsi:14 */
		pllsai: pllsai {
			compatible = "st,stm32fx-pllsai-clock"; /* in zephyr/dts/arm/st/f4/stm32f427.dtsi:15 */
			#clock-cells = < 0x0 >;                 /* in zephyr/dts/arm/st/f4/stm32f427.dtsi:16 */
			status = "disabled";                    /* in zephyr/dts/arm/st/f4/stm32f427.dtsi:17 */
		};
	};

	/* node '/mcos' defined in zephyr/dts/arm/st/f4/stm32f4.dtsi:98 */
	mcos {

		/* node '/mcos/mco1' defined in zephyr/dts/arm/st/f4/stm32f4.dtsi:99 */
		mco1: mco1 {
			compatible = "st,stm32-clock-mco"; /* in zephyr/dts/arm/st/f4/stm32f4.dtsi:100 */
			status = "disabled";               /* in zephyr/dts/arm/st/f4/stm32f4.dtsi:101 */
		};

		/* node '/mcos/mco2' defined in zephyr/dts/arm/st/f4/stm32f4.dtsi:104 */
		mco2: mco2 {
			compatible = "st,stm32-clock-mco"; /* in zephyr/dts/arm/st/f4/stm32f4.dtsi:105 */
			status = "disabled";               /* in zephyr/dts/arm/st/f4/stm32f4.dtsi:106 */
		};
	};

	/* node '/power@40007000' defined in zephyr/dts/arm/st/f4/stm32f4.dtsi:603 */
	pwr: power@40007000 {
		compatible = "st,stm32-pwr"; /* in zephyr/dts/arm/st/f4/stm32f4.dtsi:604 */
		reg = < 0x40007000 0x400 >;  /* in zephyr/dts/arm/st/f4/stm32f4.dtsi:605 */
		status = "disabled";         /* in zephyr/dts/arm/st/f4/stm32f4.dtsi:606 */
		wkup-pins-nb = < 0x1 >;      /* in zephyr/dts/arm/st/f4/stm32f4.dtsi:608 */
		#address-cells = < 0x1 >;    /* in zephyr/dts/arm/st/f4/stm32f4.dtsi:610 */
		#size-cells = < 0x0 >;       /* in zephyr/dts/arm/st/f4/stm32f4.dtsi:611 */

		/* node '/power@40007000/wkup-pin@1' defined in zephyr/dts/arm/st/f4/stm32f4.dtsi:613 */
		wkup-pin@1 {
			reg = < 0x1 >;                   /* in zephyr/dts/arm/st/f4/stm32f4.dtsi:614 */
			wkup-gpios = < &gpioa 0x0 0x1 >; /* in zephyr/dts/arm/st/f4/stm32f4.dtsi:615 */
		};
	};

	/* node '/dietemp' defined in zephyr/dts/arm/st/f4/stm32f4.dtsi:619 */
	die_temp: dietemp {
		compatible = "st,stm32-temp-cal"; /* in zephyr/dts/arm/st/f4/stm32f4.dtsi:620 */
		ts-cal1-addr = < 0x1fff7a2c >;    /* in zephyr/dts/arm/st/f4/stm32f4.dtsi:621 */
		ts-cal2-addr = < 0x1fff7a2e >;    /* in zephyr/dts/arm/st/f4/stm32f4.dtsi:622 */
		ts-cal1-temp = < 0x1e >;          /* in zephyr/dts/arm/st/f4/stm32f4.dtsi:623 */
		ts-cal2-temp = < 0x6e >;          /* in zephyr/dts/arm/st/f4/stm32f4.dtsi:624 */
		ts-cal-vrefanalog = < 0xce4 >;    /* in zephyr/dts/arm/st/f4/stm32f4.dtsi:625 */
		io-channels = < &adc1 0x12 >;     /* in zephyr/dts/arm/st/f4/stm32f427.dtsi:140 */
		status = "okay";                  /* in zephyr/boards/st/nucleo_f429zi/nucleo_f429zi.dts:103 */
	};

	/* node '/vref' defined in zephyr/dts/arm/st/f4/stm32f4.dtsi:630 */
	vref: vref {
		compatible = "st,stm32-vref";      /* in zephyr/dts/arm/st/f4/stm32f4.dtsi:631 */
		vrefint-cal-addr = < 0x1fff7a2a >; /* in zephyr/dts/arm/st/f4/stm32f4.dtsi:632 */
		vrefint-cal-mv = < 0xce4 >;        /* in zephyr/dts/arm/st/f4/stm32f4.dtsi:633 */
		io-channels = < &adc1 0x11 >;      /* in zephyr/dts/arm/st/f4/stm32f4.dtsi:634 */
		status = "okay";                   /* in zephyr/boards/st/nucleo_f429zi/nucleo_f429zi.dts:253 */
	};

	/* node '/vbat' defined in zephyr/dts/arm/st/f4/stm32f4.dtsi:638 */
	vbat: vbat {
		compatible = "st,stm32-vbat"; /* in zephyr/dts/arm/st/f4/stm32f4.dtsi:639 */
		ratio = < 0x4 >;              /* in zephyr/dts/arm/st/f4/stm32f4.dtsi:640 */
		io-channels = < &adc1 0x12 >; /* in zephyr/dts/arm/st/f4/stm32f4.dtsi:641 */
		status = "okay";              /* in zephyr/boards/st/nucleo_f429zi/nucleo_f429zi.dts:257 */
	};

	/* node '/otgfs_phy' defined in zephyr/dts/arm/st/f4/stm32f4.dtsi:645 */
	otgfs_phy: otgfs_phy {
		compatible = "usb-nop-xceiv"; /* in zephyr/dts/arm/st/f4/stm32f4.dtsi:646 */
		#phy-cells = < 0x0 >;         /* in zephyr/dts/arm/st/f4/stm32f4.dtsi:647 */
		phandle = < 0xf >;            /* in zephyr/dts/arm/st/f4/stm32f4.dtsi:322 */
	};

	/* node '/smbus1' defined in zephyr/dts/arm/st/f4/stm32f4.dtsi:650 */
	smbus1: smbus1 {
		compatible = "st,stm32-smbus"; /* in zephyr/dts/arm/st/f4/stm32f4.dtsi:651 */
		#address-cells = < 0x1 >;      /* in zephyr/dts/arm/st/f4/stm32f4.dtsi:652 */
		#size-cells = < 0x0 >;         /* in zephyr/dts/arm/st/f4/stm32f4.dtsi:653 */
		i2c = < &i2c1 >;               /* in zephyr/dts/arm/st/f4/stm32f4.dtsi:654 */
		status = "disabled";           /* in zephyr/dts/arm/st/f4/stm32f4.dtsi:655 */
	};

	/* node '/smbus2' defined in zephyr/dts/arm/st/f4/stm32f4.dtsi:658 */
	smbus2: smbus2 {
		compatible = "st,stm32-smbus"; /* in zephyr/dts/arm/st/f4/stm32f4.dtsi:659 */
		#address-cells = < 0x1 >;      /* in zephyr/dts/arm/st/f4/stm32f4.dtsi:660 */
		#size-cells = < 0x0 >;         /* in zephyr/dts/arm/st/f4/stm32f4.dtsi:661 */
		i2c = < &i2c2 >;               /* in zephyr/dts/arm/st/f4/stm32f4.dtsi:662 */
		status = "disabled";           /* in zephyr/dts/arm/st/f4/stm32f4.dtsi:663 */
	};

	/* node '/smbus3' defined in zephyr/dts/arm/st/f4/stm32f4.dtsi:666 */
	smbus3: smbus3 {
		compatible = "st,stm32-smbus"; /* in zephyr/dts/arm/st/f4/stm32f4.dtsi:667 */
		#address-cells = < 0x1 >;      /* in zephyr/dts/arm/st/f4/stm32f4.dtsi:668 */
		#size-cells = < 0x0 >;         /* in zephyr/dts/arm/st/f4/stm32f4.dtsi:669 */
		i2c = < &i2c3 >;               /* in zephyr/dts/arm/st/f4/stm32f4.dtsi:670 */
		status = "disabled";           /* in zephyr/dts/arm/st/f4/stm32f4.dtsi:671 */
	};

	/* node '/otghs_fs_phy' defined in zephyr/dts/arm/st/f4/stm32f405.dtsi:302 */
	otghs_fs_phy: otghs_fs_phy {
		compatible = "usb-nop-xceiv"; /* in zephyr/dts/arm/st/f4/stm32f405.dtsi:303 */
		#phy-cells = < 0x0 >;         /* in zephyr/dts/arm/st/f4/stm32f405.dtsi:304 */
		phandle = < 0x17 >;           /* in zephyr/dts/arm/st/f4/stm32f405.dtsi:213 */
	};

	/* node '/memory@10000000' defined in zephyr/dts/arm/st/f4/stm32f429Xi.dtsi:10 */
	ccm0: memory@10000000 {
		compatible = "zephyr,memory-region",
		             "st,stm32-ccm";         /* in zephyr/dts/arm/st/f4/stm32f429Xi.dtsi:11 */
		reg = < 0x10000000 0x10000 >;        /* in zephyr/dts/arm/st/f4/stm32f429Xi.dtsi:12 */
		zephyr,memory-region = "CCM";        /* in zephyr/dts/arm/st/f4/stm32f429Xi.dtsi:13 */
	};

	/* node '/connector' defined in zephyr/boards/st/nucleo_f429zi/arduino_r3_connector.dtsi:10 */
	arduino_header: connector {
		compatible = "arduino-header-r3";          /* in zephyr/boards/st/nucleo_f429zi/arduino_r3_connector.dtsi:11 */
		#gpio-cells = < 0x2 >;                     /* in zephyr/boards/st/nucleo_f429zi/arduino_r3_connector.dtsi:12 */
		gpio-map-mask = < 0xffffffff 0xffffffc0 >; /* in zephyr/boards/st/nucleo_f429zi/arduino_r3_connector.dtsi:13 */
		gpio-map-pass-thru = < 0x0 0x3f >;         /* in zephyr/boards/st/nucleo_f429zi/arduino_r3_connector.dtsi:14 */
		gpio-map = < 0x0 0x0 &gpioa 0x3 0x0 >,
		           < 0x1 0x0 &gpioc 0x0 0x0 >,
		           < 0x2 0x0 &gpioc 0x3 0x0 >,
		           < 0x3 0x0 &gpiof 0x3 0x0 >,
		           < 0x4 0x0 &gpiof 0x5 0x0 >,
		           < 0x5 0x0 &gpiof 0xa 0x0 >,
		           < 0x6 0x0 &gpiog 0x9 0x0 >,
		           < 0x7 0x0 &gpiog 0xe 0x0 >,
		           < 0x8 0x0 &gpiof 0xf 0x0 >,
		           < 0x9 0x0 &gpioe 0xd 0x0 >,
		           < 0xa 0x0 &gpiof 0xe 0x0 >,
		           < 0xb 0x0 &gpioe 0xb 0x0 >,
		           < 0xc 0x0 &gpioe 0x9 0x0 >,
		           < 0xd 0x0 &gpiof 0xd 0x0 >,
		           < 0xe 0x0 &gpiof 0xc 0x0 >,
		           < 0xf 0x0 &gpiod 0xf 0x0 >,
		           < 0x10 0x0 &gpiod 0xe 0x0 >,
		           < 0x11 0x0 &gpioa 0x7 0x0 >,
		           < 0x12 0x0 &gpioa 0x6 0x0 >,
		           < 0x13 0x0 &gpioa 0x5 0x0 >,
		           < 0x14 0x0 &gpiob 0x9 0x0 >,
		           < 0x15 0x0 &gpiob 0x8 0x0 >;    /* in zephyr/boards/st/nucleo_f429zi/arduino_r3_connector.dtsi:15 */
	};

	/* node '/leds' defined in zephyr/boards/st/nucleo_f429zi/nucleo_f429zi.dts:26 */
	leds: leds {
		compatible = "gpio-leds"; /* in zephyr/boards/st/nucleo_f429zi/nucleo_f429zi.dts:27 */

		/* node '/leds/led_1' defined in zephyr/boards/st/nucleo_f429zi/nucleo_f429zi.dts:29 */
		green_led_1: led_1 {
			gpios = < &gpiob 0x0 0x0 >; /* in zephyr/boards/st/nucleo_f429zi/nucleo_f429zi.dts:30 */
			label = "User LD1";         /* in zephyr/boards/st/nucleo_f429zi/nucleo_f429zi.dts:31 */
		};

		/* node '/leds/led_2' defined in zephyr/boards/st/nucleo_f429zi/nucleo_f429zi.dts:34 */
		blue_led_1: led_2 {
			gpios = < &gpiob 0x7 0x0 >; /* in zephyr/boards/st/nucleo_f429zi/nucleo_f429zi.dts:35 */
			label = "User LD2";         /* in zephyr/boards/st/nucleo_f429zi/nucleo_f429zi.dts:36 */
		};

		/* node '/leds/led_3' defined in zephyr/boards/st/nucleo_f429zi/nucleo_f429zi.dts:39 */
		red_led_1: led_3 {
			gpios = < &gpiob 0xe 0x0 >; /* in zephyr/boards/st/nucleo_f429zi/nucleo_f429zi.dts:40 */
			label = "User LD3";         /* in zephyr/boards/st/nucleo_f429zi/nucleo_f429zi.dts:41 */
		};
	};

	/* node '/gpio_keys' defined in zephyr/boards/st/nucleo_f429zi/nucleo_f429zi.dts:45 */
	gpio_keys {
		compatible = "gpio-keys"; /* in zephyr/boards/st/nucleo_f429zi/nucleo_f429zi.dts:46 */

		/* node '/gpio_keys/button' defined in zephyr/boards/st/nucleo_f429zi/nucleo_f429zi.dts:48 */
		user_button: button {
			label = "User";             /* in zephyr/boards/st/nucleo_f429zi/nucleo_f429zi.dts:49 */
			gpios = < &gpioc 0xd 0x0 >; /* in zephyr/boards/st/nucleo_f429zi/nucleo_f429zi.dts:50 */
			zephyr,code = < 0xb >;      /* in zephyr/boards/st/nucleo_f429zi/nucleo_f429zi.dts:51 */
		};
	};
};
